AUTOSAR XML (schema 00050)
package /ComponentTypes
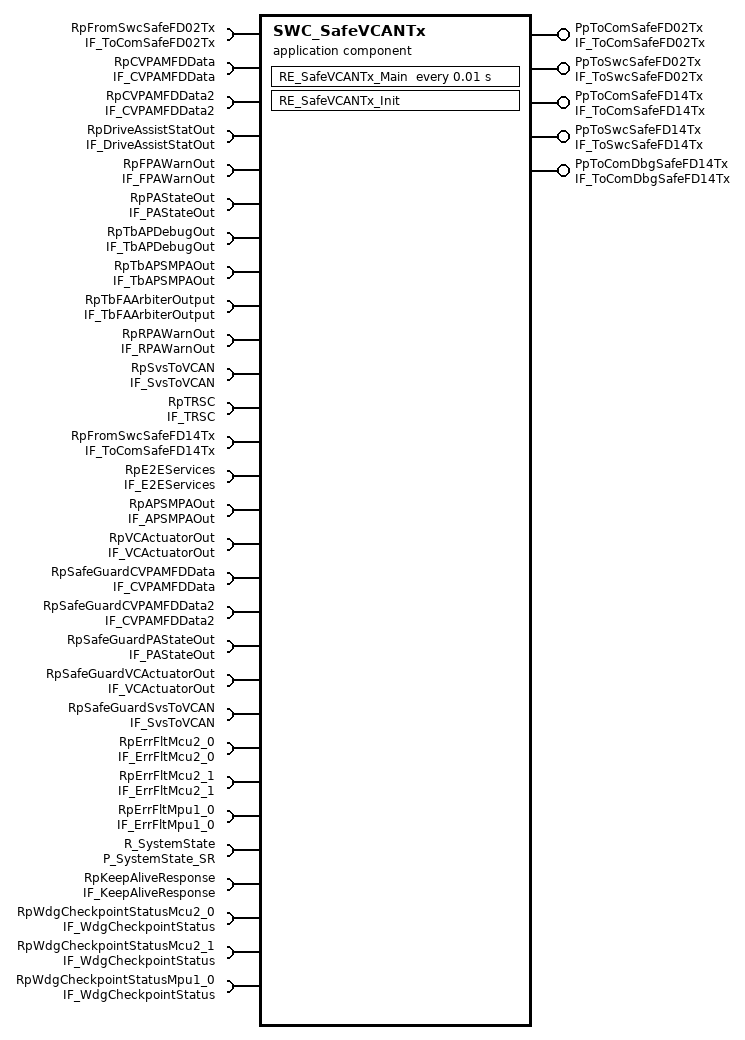
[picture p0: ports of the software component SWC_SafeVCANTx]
  application sw component type SWC_SafeVCANTx
    provide port PpToComSafeFD02Tx: provided-interface=IF_ToComSafeFD02Tx
      provided-com-specs:
        data-element=Reserved_for_functional_safety, init-value=0
        data-element=Segment_1_Confidence, init-value=0
        data-element=Segment_1_ID, init-value=0
        data-element=Segment_1_X1, init-value=0
        data-element=Segment_1_X2, init-value=0
        data-element=Segment_1_Y1, init-value=0
        data-element=Segment_1_Y2, init-value=0
        data-element=Segment_2_Confidence, init-value=0
        data-element=Segment_2_ID, init-value=0
        data-element=Segment_2_X1, init-value=0
        data-element=Segment_2_X2, init-value=0
        data-element=Segment_2_Y1, init-value=0
        data-element=Segment_2_Y2, init-value=0
        data-element=Segment_3_Confidence, init-value=0
        data-element=Segment_3_ID, init-value=0
        data-element=Segment_3_X1, init-value=0
        data-element=Segment_3_X2, init-value=0
        data-element=Segment_3_Y1, init-value=0
        data-element=Segment_3_Y2, init-value=0
        data-element=Segment_4_Confidence, init-value=0
        data-element=Segment_4_ID, init-value=0
        data-element=Segment_4_X1, init-value=0
        data-element=Segment_4_X2, init-value=0
        data-element=Segment_4_Y1, init-value=0
        data-element=Segment_4_Y2, init-value=0
        data-element=Segment_5_Confidence, init-value=0
        data-element=Segment_5_ID, init-value=0
        data-element=Segment_5_X1, init-value=0
        data-element=Segment_5_X2, init-value=0
        data-element=Segment_5_Y1, init-value=0
        data-element=Segment_5_Y2, init-value=0
        data-element=Segment_6_Confidence, init-value=0
        data-element=Segment_6_ID, init-value=0
        data-element=Segment_6_X1, init-value=0
        data-element=Segment_6_X2, init-value=0
        data-element=Segment_6_Y1, init-value=0
        data-element=Segment_6_Y2, init-value=0
        data-element=Segment_7_Confidence, init-value=0
        data-element=Segment_7_ID, init-value=0
        data-element=Segment_7_X1, init-value=0
        data-element=Segment_7_X2, init-value=0
        data-element=Segment_7_Y1, init-value=0
        data-element=Segment_7_Y2, init-value=0
        data-element=Segment_8_Confidence, init-value=0
        data-element=Segment_8_ID, init-value=0
        data-element=Segment_8_X1, init-value=0
        data-element=Segment_8_X2, init-value=0
        data-element=Segment_8_Y1, init-value=0
        data-element=Segment_8_Y2, init-value=0
        data-element=Camera_Status, init-value=0
        data-element=Cntr_ADAS_FD_LANES_1, init-value=0
        data-element=Cntr_ADAS_FD_LANES_2, init-value=0
        data-element=FOD_Confidence, init-value=0
        data-element=Frame_Index_Lanes_1, init-value=0
        data-element=Frame_Index_Lanes_2, init-value=0
        data-element=Health_Front_Object_Detection, init-value=0
        data-element=Health_Lane_Detection, init-value=0
        data-element=Line_1_Confidence, init-value=0
        data-element=Line_1_Curvature, init-value=0
        data-element=Line_1_Curvature_Rate, init-value=0
        data-element=Line_1_End_Range, init-value=0
        data-element=Line_1_Heading, init-value=0
        data-element=Line_1_Offset, init-value=0
        data-element=Line_1_Start_Range, init-value=0
        data-element=Line_1_Type, init-value=0
        data-element=Line_2_Confidence, init-value=0
        data-element=Line_2_Curvature, init-value=0
        data-element=Line_2_Curvature_Rate, init-value=0
        data-element=Line_2_End_Range, init-value=0
        data-element=Line_2_Heading, init-value=0
        data-element=Line_2_Offset, init-value=0
        data-element=Line_2_Start_Range, init-value=0
        data-element=Line_2_Type, init-value=0
        data-element=Line_3_Confidence, init-value=0
        data-element=Line_3_Curvature, init-value=0
        data-element=Line_3_Curvature_Rate, init-value=0
        data-element=Line_3_End_Range, init-value=0
        data-element=Line_3_Heading, init-value=0
        data-element=Line_3_Offset, init-value=0
        data-element=Line_3_Start_Range, init-value=0
        data-element=Line_3_Type, init-value=0
        data-element=Line_4_Confidence, init-value=0
        data-element=Line_4_Curvature, init-value=0
        data-element=Line_4_Curvature_Rate, init-value=0
        data-element=Line_4_End_Range, init-value=0
        data-element=Line_4_Heading, init-value=0
        data-element=Line_4_Offset, init-value=0
        data-element=Line_4_Start_Range, init-value=0
        data-element=Line_4_Type, init-value=0
        {data-element=MAC_ADAS_FD_LANES_1, init-value=[rule-based-values={rule=FILL_UNTIL_END, rule-arguments=0}]}
        {data-element=MAC_ADAS_FD_LANES_2, init-value=[rule-based-values={rule=FILL_UNTIL_END, rule-arguments=0}]}
        data-element=Alert_CHF, init-value=0
        data-element=Alert_CHR, init-value=0
        data-element=Alert_LHF, init-value=0
        data-element=Alert_LHR, init-value=0
        data-element=Alert_RHF, init-value=0
        data-element=Alert_RHR, init-value=0
        data-element=AUXCamsRQSts, init-value=0
        data-element=ChimeActivation_LHF, init-value=0
        data-element=ChimeActivation_LHR, init-value=0
        data-element=ChimeActivation_RHF, init-value=0
        data-element=ChimeActivation_RHR, init-value=0
        data-element=DisplayView2, init-value=0
        data-element=FrontSensorSts, init-value=0
        data-element=FT_PAM_LedControlSts, init-value=0
        data-element=Graphic_CHF, init-value=0
        data-element=Graphic_CHR, init-value=0
        data-element=Graphic_LHF, init-value=0
        data-element=Graphic_LHR, init-value=0
        data-element=Graphic_RHF, init-value=0
        data-element=Graphic_RHR, init-value=0
        data-element=HMICode, init-value=0
        data-element=ImageDefeatRQSts, init-value=0
        data-element=MoreCamsRQSts, init-value=0
        data-element=PAM_CHIME_REP_RATESts, init-value=0
        data-element=PAM_CHIME_TYPE, init-value=0
        data-element=PAM_LedControlSts, init-value=0
        data-element=PAM_Off_Status, init-value=0
        data-element=PAM_Off_Status_2BT, init-value=0
        data-element=PAM_PopUpRqst, init-value=0
        data-element=PAM_Volume, init-value=0
        data-element=PAMSystemFault, init-value=0
        data-element=ParkingManeuverActive, init-value=0
        data-element=PPPA_TurnIndicatorRqst, init-value=0
        data-element=RearSensorSts, init-value=0
        data-element=RR_PAM_Brk_RqSts, init-value=0
        data-element=RR_PAM_Dist, init-value=0
        data-element=RR_PAM_StopControlSts, init-value=0
        data-element=SPM_LedControlSts, init-value=0
        data-element=SPM_Screen_Rqst, init-value=0
        data-element=SPMControlSts, init-value=0
        data-element=SPMFailSts, init-value=0
        data-element=SPMSystemFault, init-value=0
        data-element=TRSC_LED_Stat, init-value=0
    require port RpFromSwcSafeFD02Tx: required-interface=IF_ToComSafeFD02Tx
      required-com-specs:
        data-element=Reserved_for_functional_safety, filter=data-filter-type=ALWAYS, init-value=0
        data-element=Segment_1_Confidence, filter=data-filter-type=ALWAYS, init-value=0
        data-element=Segment_1_ID, filter=data-filter-type=ALWAYS, init-value=0
        data-element=Segment_1_X1, filter=data-filter-type=ALWAYS, init-value=0
        data-element=Segment_1_X2, filter=data-filter-type=ALWAYS, init-value=0
        data-element=Segment_1_Y1, filter=data-filter-type=ALWAYS, init-value=0
        data-element=Segment_1_Y2, filter=data-filter-type=ALWAYS, init-value=0
        data-element=Segment_2_Confidence, filter=data-filter-type=ALWAYS, init-value=0
        data-element=Segment_2_ID, filter=data-filter-type=ALWAYS, init-value=0
        data-element=Segment_2_X1, filter=data-filter-type=ALWAYS, init-value=0
        data-element=Segment_2_X2, filter=data-filter-type=ALWAYS, init-value=0
        data-element=Segment_2_Y1, filter=data-filter-type=ALWAYS, init-value=0
        data-element=Segment_2_Y2, filter=data-filter-type=ALWAYS, init-value=0
        data-element=Segment_3_Confidence, filter=data-filter-type=ALWAYS, init-value=0
        data-element=Segment_3_ID, filter=data-filter-type=ALWAYS, init-value=0
        data-element=Segment_3_X1, filter=data-filter-type=ALWAYS, init-value=0
        data-element=Segment_3_X2, filter=data-filter-type=ALWAYS, init-value=0
        data-element=Segment_3_Y1, filter=data-filter-type=ALWAYS, init-value=0
        data-element=Segment_3_Y2, filter=data-filter-type=ALWAYS, init-value=0
        data-element=Segment_4_Confidence, filter=data-filter-type=ALWAYS, init-value=0
        data-element=Segment_4_ID, filter=data-filter-type=ALWAYS, init-value=0
        data-element=Segment_4_X1, filter=data-filter-type=ALWAYS, init-value=0
        data-element=Segment_4_X2, filter=data-filter-type=ALWAYS, init-value=0
        data-element=Segment_4_Y1, filter=data-filter-type=ALWAYS, init-value=0
        data-element=Segment_4_Y2, filter=data-filter-type=ALWAYS, init-value=0
        data-element=Segment_5_Confidence, filter=data-filter-type=ALWAYS, init-value=0
        data-element=Segment_5_ID, filter=data-filter-type=ALWAYS, init-value=0
        data-element=Segment_5_X1, filter=data-filter-type=ALWAYS, init-value=0
        data-element=Segment_5_X2, filter=data-filter-type=ALWAYS, init-value=0
        data-element=Segment_5_Y1, filter=data-filter-type=ALWAYS, init-value=0
        data-element=Segment_5_Y2, filter=data-filter-type=ALWAYS, init-value=0
        data-element=Segment_6_Confidence, filter=data-filter-type=ALWAYS, init-value=0
        data-element=Segment_6_ID, filter=data-filter-type=ALWAYS, init-value=0
        data-element=Segment_6_X1, filter=data-filter-type=ALWAYS, init-value=0
        data-element=Segment_6_X2, filter=data-filter-type=ALWAYS, init-value=0
        data-element=Segment_6_Y1, filter=data-filter-type=ALWAYS, init-value=0
        data-element=Segment_6_Y2, filter=data-filter-type=ALWAYS, init-value=0
        data-element=Segment_7_Confidence, filter=data-filter-type=ALWAYS, init-value=0
        data-element=Segment_7_ID, filter=data-filter-type=ALWAYS, init-value=0
        data-element=Segment_7_X1, filter=data-filter-type=ALWAYS, init-value=0
        data-element=Segment_7_X2, filter=data-filter-type=ALWAYS, init-value=0
        data-element=Segment_7_Y1, filter=data-filter-type=ALWAYS, init-value=0
        data-element=Segment_7_Y2, filter=data-filter-type=ALWAYS, init-value=0
        data-element=Segment_8_Confidence, filter=data-filter-type=ALWAYS, init-value=0
        data-element=Segment_8_ID, filter=data-filter-type=ALWAYS, init-value=0
        data-element=Segment_8_X1, filter=data-filter-type=ALWAYS, init-value=0
        data-element=Segment_8_X2, filter=data-filter-type=ALWAYS, init-value=0
        data-element=Segment_8_Y1, filter=data-filter-type=ALWAYS, init-value=0
        data-element=Segment_8_Y2, filter=data-filter-type=ALWAYS, init-value=0
        data-element=Camera_Status, filter=data-filter-type=ALWAYS, init-value=0
        data-element=Cntr_ADAS_FD_LANES_1, filter=data-filter-type=ALWAYS, init-value=0
        data-element=Cntr_ADAS_FD_LANES_2, filter=data-filter-type=ALWAYS, init-value=0
        data-element=FOD_Confidence, filter=data-filter-type=ALWAYS, init-value=0
        data-element=Frame_Index_Lanes_1, filter=data-filter-type=ALWAYS, init-value=0
        data-element=Frame_Index_Lanes_2, filter=data-filter-type=ALWAYS, init-value=0
        data-element=Health_Front_Object_Detection, filter=data-filter-type=ALWAYS, init-value=0
        data-element=Health_Lane_Detection, filter=data-filter-type=ALWAYS, init-value=0
        data-element=Line_1_Confidence, filter=data-filter-type=ALWAYS, init-value=0
        data-element=Line_1_Curvature, filter=data-filter-type=ALWAYS, init-value=0
        data-element=Line_1_Curvature_Rate, filter=data-filter-type=ALWAYS, init-value=0
        data-element=Line_1_End_Range, filter=data-filter-type=ALWAYS, init-value=0
        data-element=Line_1_Heading, filter=data-filter-type=ALWAYS, init-value=0
        data-element=Line_1_Offset, filter=data-filter-type=ALWAYS, init-value=0
        data-element=Line_1_Start_Range, filter=data-filter-type=ALWAYS, init-value=0
        data-element=Line_1_Type, filter=data-filter-type=ALWAYS, init-value=0
        data-element=Line_2_Confidence, filter=data-filter-type=ALWAYS, init-value=0
        data-element=Line_2_Curvature, filter=data-filter-type=ALWAYS, init-value=0
        data-element=Line_2_Curvature_Rate, filter=data-filter-type=ALWAYS, init-value=0
        data-element=Line_2_End_Range, filter=data-filter-type=ALWAYS, init-value=0
        data-element=Line_2_Heading, filter=data-filter-type=ALWAYS, init-value=0
        data-element=Line_2_Offset, filter=data-filter-type=ALWAYS, init-value=0
        data-element=Line_2_Start_Range, filter=data-filter-type=ALWAYS, init-value=0
        data-element=Line_2_Type, filter=data-filter-type=ALWAYS, init-value=0
        data-element=Line_3_Confidence, filter=data-filter-type=ALWAYS, init-value=0
        data-element=Line_3_Curvature, filter=data-filter-type=ALWAYS, init-value=0
        data-element=Line_3_Curvature_Rate, filter=data-filter-type=ALWAYS, init-value=0
        data-element=Line_3_End_Range, filter=data-filter-type=ALWAYS, init-value=0
        data-element=Line_3_Heading, filter=data-filter-type=ALWAYS, init-value=0
        data-element=Line_3_Offset, filter=data-filter-type=ALWAYS, init-value=0
        data-element=Line_3_Start_Range, filter=data-filter-type=ALWAYS, init-value=0
        data-element=Line_3_Type, filter=data-filter-type=ALWAYS, init-value=0
        data-element=Line_4_Confidence, filter=data-filter-type=ALWAYS, init-value=0
        data-element=Line_4_Curvature, filter=data-filter-type=ALWAYS, init-value=0
        data-element=Line_4_Curvature_Rate, filter=data-filter-type=ALWAYS, init-value=0
        data-element=Line_4_End_Range, filter=data-filter-type=ALWAYS, init-value=0
        data-element=Line_4_Heading, filter=data-filter-type=ALWAYS, init-value=0
        data-element=Line_4_Offset, filter=data-filter-type=ALWAYS, init-value=0
        data-element=Line_4_Start_Range, filter=data-filter-type=ALWAYS, init-value=0
        data-element=Line_4_Type, filter=data-filter-type=ALWAYS, init-value=0
        {data-element=MAC_ADAS_FD_LANES_1, filter=data-filter-type=ALWAYS, init-value=[rule-based-values={rule=FILL_UNTIL_END, rule-arguments=0}]}
        {data-element=MAC_ADAS_FD_LANES_2, filter=data-filter-type=ALWAYS, init-value=[rule-based-values={rule=FILL_UNTIL_END, rule-arguments=0}]}
        data-element=Alert_CHF, filter=data-filter-type=ALWAYS, init-value=0
        data-element=Alert_CHR, filter=data-filter-type=ALWAYS, init-value=0
        data-element=Alert_LHF, filter=data-filter-type=ALWAYS, init-value=0
        data-element=Alert_LHR, filter=data-filter-type=ALWAYS, init-value=0
        data-element=Alert_RHF, filter=data-filter-type=ALWAYS, init-value=0
        data-element=Alert_RHR, filter=data-filter-type=ALWAYS, init-value=0
        data-element=AUXCamsRQSts, filter=data-filter-type=ALWAYS, init-value=0
        data-element=ChimeActivation_LHF, filter=data-filter-type=ALWAYS, init-value=0
        data-element=ChimeActivation_LHR, filter=data-filter-type=ALWAYS, init-value=0
        data-element=ChimeActivation_RHF, filter=data-filter-type=ALWAYS, init-value=0
        data-element=ChimeActivation_RHR, filter=data-filter-type=ALWAYS, init-value=0
        data-element=DisplayView2, filter=data-filter-type=ALWAYS, init-value=0
        data-element=FrontSensorSts, filter=data-filter-type=ALWAYS, init-value=0
        data-element=FT_PAM_LedControlSts, filter=data-filter-type=ALWAYS, init-value=0
        data-element=Graphic_CHF, filter=data-filter-type=ALWAYS, init-value=0
        data-element=Graphic_CHR, filter=data-filter-type=ALWAYS, init-value=0
        data-element=Graphic_LHF, filter=data-filter-type=ALWAYS, init-value=0
        data-element=Graphic_LHR, filter=data-filter-type=ALWAYS, init-value=0
        data-element=Graphic_RHF, filter=data-filter-type=ALWAYS, init-value=0
        data-element=Graphic_RHR, filter=data-filter-type=ALWAYS, init-value=0
        data-element=HMICode, filter=data-filter-type=ALWAYS, init-value=0
        data-element=ImageDefeatRQSts, filter=data-filter-type=ALWAYS, init-value=0
        data-element=MoreCamsRQSts, filter=data-filter-type=ALWAYS, init-value=0
        data-element=PAM_CHIME_REP_RATESts, filter=data-filter-type=ALWAYS, init-value=0
        data-element=PAM_CHIME_TYPE, filter=data-filter-type=ALWAYS, init-value=0
        data-element=PAM_LedControlSts, filter=data-filter-type=ALWAYS, init-value=0
        data-element=PAM_Off_Status, filter=data-filter-type=ALWAYS, init-value=0
        data-element=PAM_Off_Status_2BT, filter=data-filter-type=ALWAYS, init-value=0
        data-element=PAM_PopUpRqst, filter=data-filter-type=ALWAYS, init-value=0
        data-element=PAM_Volume, filter=data-filter-type=ALWAYS, init-value=0
        data-element=PAMSystemFault, filter=data-filter-type=ALWAYS, init-value=0
        data-element=ParkingManeuverActive, filter=data-filter-type=ALWAYS, init-value=0
        data-element=PPPA_TurnIndicatorRqst, filter=data-filter-type=ALWAYS, init-value=0
        data-element=RearSensorSts, filter=data-filter-type=ALWAYS, init-value=0
        data-element=RR_PAM_Brk_RqSts, filter=data-filter-type=ALWAYS, init-value=0
        data-element=RR_PAM_Dist, filter=data-filter-type=ALWAYS, init-value=0
        data-element=RR_PAM_StopControlSts, filter=data-filter-type=ALWAYS, init-value=0
        data-element=SPM_LedControlSts, filter=data-filter-type=ALWAYS, init-value=0
        data-element=SPM_Screen_Rqst, filter=data-filter-type=ALWAYS, init-value=0
        data-element=SPMControlSts, filter=data-filter-type=ALWAYS, init-value=0
        data-element=SPMFailSts, filter=data-filter-type=ALWAYS, init-value=0
        data-element=SPMSystemFault, filter=data-filter-type=ALWAYS, init-value=0
        data-element=TRSC_LED_Stat, filter=data-filter-type=ALWAYS, init-value=0
    provide port PpToSwcSafeFD02Tx: provided-interface=IF_ToSwcSafeFD02Tx
      provided-com-specs:
        data-element=Reserved_for_functional_safety, init-value=0
        data-element=Segment_1_Confidence, init-value=0
        data-element=Segment_1_ID, init-value=0
        data-element=Segment_1_X1, init-value=0
        data-element=Segment_1_X2, init-value=0
        data-element=Segment_1_Y1, init-value=0
        data-element=Segment_1_Y2, init-value=0
        data-element=Segment_2_Confidence, init-value=0
        data-element=Segment_2_ID, init-value=0
        data-element=Segment_2_X1, init-value=0
        data-element=Segment_2_X2, init-value=0
        data-element=Segment_2_Y1, init-value=0
        data-element=Segment_2_Y2, init-value=0
        data-element=Segment_3_Confidence, init-value=0
        data-element=Segment_3_ID, init-value=0
        data-element=Segment_3_X1, init-value=0
        data-element=Segment_3_X2, init-value=0
        data-element=Segment_3_Y1, init-value=0
        data-element=Segment_3_Y2, init-value=0
        data-element=Segment_4_Confidence, init-value=0
        data-element=Segment_4_ID, init-value=0
        data-element=Segment_4_X1, init-value=0
        data-element=Segment_4_X2, init-value=0
        data-element=Segment_4_Y1, init-value=0
        data-element=Segment_4_Y2, init-value=0
        data-element=Segment_5_Confidence, init-value=0
        data-element=Segment_5_ID, init-value=0
        data-element=Segment_5_X1, init-value=0
        data-element=Segment_5_X2, init-value=0
        data-element=Segment_5_Y1, init-value=0
        data-element=Segment_5_Y2, init-value=0
        data-element=Segment_6_Confidence, init-value=0
        data-element=Segment_6_ID, init-value=0
        data-element=Segment_6_X1, init-value=0
        data-element=Segment_6_X2, init-value=0
        data-element=Segment_6_Y1, init-value=0
        data-element=Segment_6_Y2, init-value=0
        data-element=Segment_7_Confidence, init-value=0
        data-element=Segment_7_ID, init-value=0
        data-element=Segment_7_X1, init-value=0
        data-element=Segment_7_X2, init-value=0
        data-element=Segment_7_Y1, init-value=0
        data-element=Segment_7_Y2, init-value=0
        data-element=Segment_8_Confidence, init-value=0
        data-element=Segment_8_ID, init-value=0
        data-element=Segment_8_X1, init-value=0
        data-element=Segment_8_X2, init-value=0
        data-element=Segment_8_Y1, init-value=0
        data-element=Segment_8_Y2, init-value=0
        data-element=Camera_Status, init-value=0
        data-element=Cntr_ADAS_FD_LANES_1, init-value=0
        data-element=Cntr_ADAS_FD_LANES_2, init-value=0
        data-element=FOD_Confidence, init-value=0
        data-element=Frame_Index_Lanes_1, init-value=0
        data-element=Frame_Index_Lanes_2, init-value=0
        data-element=Health_Front_Object_Detection, init-value=0
        data-element=Health_Lane_Detection, init-value=0
        data-element=Line_1_Confidence, init-value=0
        data-element=Line_1_Curvature, init-value=0
        data-element=Line_1_Curvature_Rate, init-value=0
        data-element=Line_1_End_Range, init-value=0
        data-element=Line_1_Heading, init-value=0
        data-element=Line_1_Offset, init-value=0
        data-element=Line_1_Start_Range, init-value=0
        data-element=Line_1_Type, init-value=0
        data-element=Line_2_Confidence, init-value=0
        data-element=Line_2_Curvature, init-value=0
        data-element=Line_2_Curvature_Rate, init-value=0
        data-element=Line_2_End_Range, init-value=0
        data-element=Line_2_Heading, init-value=0
        data-element=Line_2_Offset, init-value=0
        data-element=Line_2_Start_Range, init-value=0
        data-element=Line_2_Type, init-value=0
        data-element=Line_3_Confidence, init-value=0
        data-element=Line_3_Curvature, init-value=0
        data-element=Line_3_Curvature_Rate, init-value=0
        data-element=Line_3_End_Range, init-value=0
        data-element=Line_3_Heading, init-value=0
        data-element=Line_3_Offset, init-value=0
        data-element=Line_3_Start_Range, init-value=0
        data-element=Line_3_Type, init-value=0
        data-element=Line_4_Confidence, init-value=0
        data-element=Line_4_Curvature, init-value=0
        data-element=Line_4_Curvature_Rate, init-value=0
        data-element=Line_4_End_Range, init-value=0
        data-element=Line_4_Heading, init-value=0
        data-element=Line_4_Offset, init-value=0
        data-element=Line_4_Start_Range, init-value=0
        data-element=Line_4_Type, init-value=0
        {data-element=MAC_ADAS_FD_LANES_1, init-value=[rule-based-values={rule=FILL_UNTIL_END, rule-arguments=0}]}
        {data-element=MAC_ADAS_FD_LANES_2, init-value=[rule-based-values={rule=FILL_UNTIL_END, rule-arguments=0}]}
        data-element=Alert_CHF, init-value=0
        data-element=Alert_CHR, init-value=0
        data-element=Alert_LHF, init-value=0
        data-element=Alert_LHR, init-value=0
        data-element=Alert_RHF, init-value=0
        data-element=Alert_RHR, init-value=0
        data-element=AUXCamsRQSts, init-value=0
        data-element=ChimeActivation_LHF, init-value=0
        data-element=ChimeActivation_LHR, init-value=0
        data-element=ChimeActivation_RHF, init-value=0
        data-element=ChimeActivation_RHR, init-value=0
        data-element=DisplayView2, init-value=0
        data-element=FrontSensorSts, init-value=0
        data-element=FT_PAM_LedControlSts, init-value=0
        data-element=Graphic_CHF, init-value=0
        data-element=Graphic_CHR, init-value=0
        data-element=Graphic_LHF, init-value=0
        data-element=Graphic_LHR, init-value=0
        data-element=Graphic_RHF, init-value=0
        data-element=Graphic_RHR, init-value=0
        data-element=HMICode, init-value=0
        data-element=ImageDefeatRQSts, init-value=0
        data-element=MoreCamsRQSts, init-value=0
        data-element=PAM_CHIME_REP_RATESts, init-value=0
        data-element=PAM_CHIME_TYPE, init-value=0
        data-element=PAM_LedControlSts, init-value=0
        data-element=PAM_Off_Status, init-value=0
        data-element=PAM_Off_Status_2BT, init-value=0
        data-element=PAM_PopUpRqst, init-value=0
        data-element=PAM_Volume, init-value=0
        data-element=PAMSystemFault, init-value=0
        data-element=ParkingManeuverActive, init-value=0
        data-element=PPPA_TurnIndicatorRqst, init-value=0
        data-element=RearSensorSts, init-value=0
        data-element=RR_PAM_Brk_RqSts, init-value=0
        data-element=RR_PAM_Dist, init-value=0
        data-element=RR_PAM_StopControlSts, init-value=0
        data-element=SPM_LedControlSts, init-value=0
        data-element=SPM_Screen_Rqst, init-value=0
        data-element=SPMControlSts, init-value=0
        data-element=SPMFailSts, init-value=0
        data-element=SPMSystemFault, init-value=0
        data-element=TRSC_LED_Stat, init-value=0
    11 x require port:
      RpCVPAMFDData: nonqueued-receiver-com-spec=data-element=IFOD_Outputs_CVPAMFDData_t, required-interface=IF_CVPAMFDData
      RpCVPAMFDData2: nonqueued-receiver-com-spec=data-element=LMD_Outputs_CVPAMFDData2_t, required-interface=IF_CVPAMFDData2
      RpDriveAssistStatOut: nonqueued-receiver-com-spec=data-element=TbAP_DriveAssistStatOut_t, required-interface=IF_DriveAssistStatOut
      RpFPAWarnOut: nonqueued-receiver-com-spec=data-element=TbAP_FPAWarnOut_t, required-interface=IF_FPAWarnOut
      RpPAStateOut: nonqueued-receiver-com-spec=data-element=TbAP_PAStateOut_t, required-interface=IF_PAStateOut
      RpTbAPDebugOut: nonqueued-receiver-com-spec=data-element=TbAP_DebugOut, required-interface=IF_TbAPDebugOut
      RpTbAPSMPAOut: nonqueued-receiver-com-spec=data-element=TbAP_SMPAInternalOut_t, required-interface=IF_TbAPSMPAOut
      RpTbFAArbiterOutput: nonqueued-receiver-com-spec{data-element=TbFA_ArbiterOutput_t, filter=data-filter-type=ALWAYS}, required-interface=IF_TbFAArbiterOutput
      RpRPAWarnOut: nonqueued-receiver-com-spec=data-element=TbAP_RPAWarnOut_t, required-interface=IF_RPAWarnOut
      RpSvsToVCAN: nonqueued-receiver-com-spec=data-element=SvsToVCAN_t, required-interface=IF_SvsToVCAN
      RpTRSC: nonqueued-receiver-com-spec=data-element=ME_VehOut_TRSC_t, required-interface=IF_TRSC
    provide port PpToComSafeFD14Tx: provided-interface=IF_ToComSafeFD14Tx
      provided-com-specs:
        data-element=FD14_Camera_Status, init-value=0
        data-element=FD14_Cntr_ADAS_FD_LANES_1, init-value=0
        data-element=FD14_Cntr_ADAS_FD_LANES_2, init-value=0
        data-element=FD14_FOD_Confidence, init-value=0
        data-element=FD14_Frame_Index_Lanes_1, init-value=0
        data-element=FD14_Frame_Index_Lanes_2, init-value=0
        data-element=FD14_Health_Front_Object_Detection, init-value=0
        data-element=FD14_Health_Lane_Detection, init-value=0
        data-element=FD14_Line_1_Confidence, init-value=0
        data-element=FD14_Line_1_Curvature, init-value=0
        data-element=FD14_Line_1_Curvature_Rate, init-value=0
        data-element=FD14_Line_1_End_Range, init-value=0
        data-element=FD14_Line_1_Heading, init-value=0
        data-element=FD14_Line_1_Offset, init-value=0
        data-element=FD14_Line_1_Start_Range, init-value=0
        data-element=FD14_Line_1_Type, init-value=0
        data-element=FD14_Line_2_Confidence, init-value=0
        data-element=FD14_Line_2_Curvature, init-value=0
        data-element=FD14_Line_2_Curvature_Rate, init-value=0
        data-element=FD14_Line_2_End_Range, init-value=0
        data-element=FD14_Line_2_Heading, init-value=0
        data-element=FD14_Line_2_Offset, init-value=0
        data-element=FD14_Line_2_Start_Range, init-value=0
        data-element=FD14_Line_2_Type, init-value=0
        data-element=FD14_Line_3_Confidence, init-value=0
        data-element=FD14_Line_3_Curvature, init-value=0
        data-element=FD14_Line_3_Curvature_Rate, init-value=0
        data-element=FD14_Line_3_End_Range, init-value=0
        data-element=FD14_Line_3_Heading, init-value=0
        data-element=FD14_Line_3_Offset, init-value=0
        data-element=FD14_Line_3_Start_Range, init-value=0
        data-element=FD14_Line_3_Type, init-value=0
        data-element=FD14_Line_4_Confidence, init-value=0
        data-element=FD14_Line_4_Curvature, init-value=0
        data-element=FD14_Line_4_Curvature_Rate, init-value=0
        data-element=FD14_Line_4_End_Range, init-value=0
        data-element=FD14_Line_4_Heading, init-value=0
        data-element=FD14_Line_4_Offset, init-value=0
        data-element=FD14_Line_4_Start_Range, init-value=0
        data-element=FD14_Line_4_Type, init-value=0
        {data-element=FD14_MAC_ADAS_FD_LANES_1, init-value=[rule-based-values={rule=FILL_UNTIL_END, rule-arguments=0}]}
        {data-element=FD14_MAC_ADAS_FD_LANES_2, init-value=[rule-based-values={rule=FILL_UNTIL_END, rule-arguments=0}]}
        data-element=FD14_ParkingManeuverActive, init-value=0
        data-element=FD14_Reserved_for_functional_safety, init-value=0
        data-element=FD14_Segment_1_Confidence, init-value=0
        data-element=FD14_Segment_1_ID, init-value=0
        data-element=FD14_Segment_1_X1, init-value=0
        data-element=FD14_Segment_1_X2, init-value=0
        data-element=FD14_Segment_1_Y1, init-value=0
        data-element=FD14_Segment_1_Y2, init-value=0
        data-element=FD14_Segment_2_Confidence, init-value=0
        data-element=FD14_Segment_2_ID, init-value=0
        data-element=FD14_Segment_2_X1, init-value=0
        data-element=FD14_Segment_2_X2, init-value=0
        data-element=FD14_Segment_2_Y1, init-value=0
        data-element=FD14_Segment_2_Y2, init-value=0
        data-element=FD14_Segment_3_Confidence, init-value=0
        data-element=FD14_Segment_3_ID, init-value=0
        data-element=FD14_Segment_3_X1, init-value=0
        data-element=FD14_Segment_3_X2, init-value=0
        data-element=FD14_Segment_3_Y1, init-value=0
        data-element=FD14_Segment_3_Y2, init-value=0
        data-element=FD14_Segment_4_Confidence, init-value=0
        data-element=FD14_Segment_4_ID, init-value=0
        data-element=FD14_Segment_4_X1, init-value=0
        data-element=FD14_Segment_4_X2, init-value=0
        data-element=FD14_Segment_4_Y1, init-value=0
        data-element=FD14_Segment_4_Y2, init-value=0
        data-element=FD14_Segment_5_Confidence, init-value=0
        data-element=FD14_Segment_5_ID, init-value=0
        data-element=FD14_Segment_5_X1, init-value=0
        data-element=FD14_Segment_5_X2, init-value=0
        data-element=FD14_Segment_5_Y1, init-value=0
        data-element=FD14_Segment_5_Y2, init-value=0
        data-element=FD14_Segment_6_Confidence, init-value=0
        data-element=FD14_Segment_6_ID, init-value=0
        data-element=FD14_Segment_6_X1, init-value=0
        data-element=FD14_Segment_6_X2, init-value=0
        data-element=FD14_Segment_6_Y1, init-value=0
        data-element=FD14_Segment_6_Y2, init-value=0
        data-element=FD14_Segment_7_Confidence, init-value=0
        data-element=FD14_Segment_7_ID, init-value=0
        data-element=FD14_Segment_7_X1, init-value=0
        data-element=FD14_Segment_7_X2, init-value=0
        data-element=FD14_Segment_7_Y1, init-value=0
        data-element=FD14_Segment_7_Y2, init-value=0
        data-element=FD14_Segment_8_Confidence, init-value=0
        data-element=FD14_Segment_8_ID, init-value=0
        data-element=FD14_Segment_8_X1, init-value=0
        data-element=FD14_Segment_8_X2, init-value=0
        data-element=FD14_Segment_8_Y1, init-value=0
        data-element=FD14_Segment_8_Y2, init-value=0
        data-element=FD14_ManoeuvrePhase, init-value=0
        data-element=FD14_ParkingGearShiftReq, init-value=0
        data-element=FD14_PPPA_AccelMax, init-value=0
        data-element=FD14_PPPA_AccelMin, init-value=0
        data-element=FD14_PPPA_DecelMax, init-value=0
        data-element=FD14_PPPA_DecelMin, init-value=0
        data-element=FD14_PPPA_Interface_BSM, init-value=0
        data-element=FD14_PPPA_JerkAccelMax, init-value=0
        data-element=FD14_PPPA_JerkAccelMin, init-value=0
        data-element=FD14_PPPA_JerkDecelMax, init-value=0
        data-element=FD14_PPPA_JerkDecelMin, init-value=0
        data-element=FD14_PPPA_MaxSpeed, init-value=0
        data-element=FD14_PPPA_StandstillRqst, init-value=0
        data-element=FD14_PPPA_TargetDistance, init-value=0
        data-element=FD14_RR_PAM_Brk_RqSts, init-value=0
        data-element=FD14_RR_PAM_Dist, init-value=0
        data-element=FD14_SPM_Lat_Ctrl_RequestSts, init-value=0
        data-element=FD14_TorqueOverlaySteeringReq_SPM, init-value=1024
    provide port PpToSwcSafeFD14Tx: provided-interface=IF_ToSwcSafeFD14Tx
      provided-com-specs:
        data-element=FD14_Camera_Status, init-value=0
        data-element=FD14_Cntr_ADAS_FD_LANES_1, init-value=0
        data-element=FD14_Cntr_ADAS_FD_LANES_2, init-value=0
        data-element=FD14_FOD_Confidence, init-value=0
        data-element=FD14_Frame_Index_Lanes_1, init-value=0
        data-element=FD14_Frame_Index_Lanes_2, init-value=0
        data-element=FD14_Health_Front_Object_Detection, init-value=0
        data-element=FD14_Health_Lane_Detection, init-value=0
        data-element=FD14_Line_1_Confidence, init-value=0
        data-element=FD14_Line_1_Curvature, init-value=0
        data-element=FD14_Line_1_Curvature_Rate, init-value=0
        data-element=FD14_Line_1_End_Range, init-value=0
        data-element=FD14_Line_1_Heading, init-value=0
        data-element=FD14_Line_1_Offset, init-value=0
        data-element=FD14_Line_1_Start_Range, init-value=0
        data-element=FD14_Line_1_Type, init-value=0
        data-element=FD14_Line_2_Confidence, init-value=0
        data-element=FD14_Line_2_Curvature, init-value=0
        data-element=FD14_Line_2_Curvature_Rate, init-value=0
        data-element=FD14_Line_2_End_Range, init-value=0
        data-element=FD14_Line_2_Heading, init-value=0
        data-element=FD14_Line_2_Offset, init-value=0
        data-element=FD14_Line_2_Start_Range, init-value=0
        data-element=FD14_Line_2_Type, init-value=0
        data-element=FD14_Line_3_Confidence, init-value=0
        data-element=FD14_Line_3_Curvature, init-value=0
        data-element=FD14_Line_3_Curvature_Rate, init-value=0
        data-element=FD14_Line_3_End_Range, init-value=0
        data-element=FD14_Line_3_Heading, init-value=0
        data-element=FD14_Line_3_Offset, init-value=0
        data-element=FD14_Line_3_Start_Range, init-value=0
        data-element=FD14_Line_3_Type, init-value=0
        data-element=FD14_Line_4_Confidence, init-value=0
        data-element=FD14_Line_4_Curvature, init-value=0
        data-element=FD14_Line_4_Curvature_Rate, init-value=0
        data-element=FD14_Line_4_End_Range, init-value=0
        data-element=FD14_Line_4_Heading, init-value=0
        data-element=FD14_Line_4_Offset, init-value=0
        data-element=FD14_Line_4_Start_Range, init-value=0
        data-element=FD14_Line_4_Type, init-value=0
        {data-element=FD14_MAC_ADAS_FD_LANES_1, init-value=[rule-based-values={rule=FILL_UNTIL_END, rule-arguments=0}]}
        {data-element=FD14_MAC_ADAS_FD_LANES_2, init-value=[rule-based-values={rule=FILL_UNTIL_END, rule-arguments=0}]}
        data-element=FD14_ParkingManeuverActive, init-value=0
        data-element=FD14_Reserved_for_functional_safety, init-value=0
        data-element=FD14_Segment_1_Confidence, init-value=0
        data-element=FD14_Segment_1_ID, init-value=0
        data-element=FD14_Segment_1_X1, init-value=0
        data-element=FD14_Segment_1_X2, init-value=0
        data-element=FD14_Segment_1_Y1, init-value=0
        data-element=FD14_Segment_1_Y2, init-value=0
        data-element=FD14_Segment_2_Confidence, init-value=0
        data-element=FD14_Segment_2_ID, init-value=0
        data-element=FD14_Segment_2_X1, init-value=0
        data-element=FD14_Segment_2_X2, init-value=0
        data-element=FD14_Segment_2_Y1, init-value=0
        data-element=FD14_Segment_2_Y2, init-value=0
        data-element=FD14_Segment_3_Confidence, init-value=0
        data-element=FD14_Segment_3_ID, init-value=0
        data-element=FD14_Segment_3_X1, init-value=0
        data-element=FD14_Segment_3_X2, init-value=0
        data-element=FD14_Segment_3_Y1, init-value=0
        data-element=FD14_Segment_3_Y2, init-value=0
        data-element=FD14_Segment_4_Confidence, init-value=0
        data-element=FD14_Segment_4_ID, init-value=0
        data-element=FD14_Segment_4_X1, init-value=0
        data-element=FD14_Segment_4_X2, init-value=0
        data-element=FD14_Segment_4_Y1, init-value=0
        data-element=FD14_Segment_4_Y2, init-value=0
        data-element=FD14_Segment_5_Confidence, init-value=0
        data-element=FD14_Segment_5_ID, init-value=0
        data-element=FD14_Segment_5_X1, init-value=0
        data-element=FD14_Segment_5_X2, init-value=0
        data-element=FD14_Segment_5_Y1, init-value=0
        data-element=FD14_Segment_5_Y2, init-value=0
        data-element=FD14_Segment_6_Confidence, init-value=0
        data-element=FD14_Segment_6_ID, init-value=0
        data-element=FD14_Segment_6_X1, init-value=0
        data-element=FD14_Segment_6_X2, init-value=0
        data-element=FD14_Segment_6_Y1, init-value=0
        data-element=FD14_Segment_6_Y2, init-value=0
        data-element=FD14_Segment_7_Confidence, init-value=0
        data-element=FD14_Segment_7_ID, init-value=0
        data-element=FD14_Segment_7_X1, init-value=0
        data-element=FD14_Segment_7_X2, init-value=0
        data-element=FD14_Segment_7_Y1, init-value=0
        data-element=FD14_Segment_7_Y2, init-value=0
        data-element=FD14_Segment_8_Confidence, init-value=0
        data-element=FD14_Segment_8_ID, init-value=0
        data-element=FD14_Segment_8_X1, init-value=0
        data-element=FD14_Segment_8_X2, init-value=0
        data-element=FD14_Segment_8_Y1, init-value=0
        data-element=FD14_Segment_8_Y2, init-value=0
        data-element=FD14_ManoeuvrePhase, init-value=0
        data-element=FD14_ParkingGearShiftReq, init-value=0
        data-element=FD14_PPPA_AccelMax, init-value=0
        data-element=FD14_PPPA_AccelMin, init-value=0
        data-element=FD14_PPPA_DecelMax, init-value=0
        data-element=FD14_PPPA_DecelMin, init-value=0
        data-element=FD14_PPPA_Interface_BSM, init-value=0
        data-element=FD14_PPPA_JerkAccelMax, init-value=0
        data-element=FD14_PPPA_JerkAccelMin, init-value=0
        data-element=FD14_PPPA_JerkDecelMax, init-value=0
        data-element=FD14_PPPA_JerkDecelMin, init-value=0
        data-element=FD14_PPPA_MaxSpeed, init-value=0
        data-element=FD14_PPPA_StandstillRqst, init-value=0
        data-element=FD14_PPPA_TargetDistance, init-value=0
        data-element=FD14_RR_PAM_Brk_RqSts, init-value=0
        data-element=FD14_RR_PAM_Dist, init-value=0
        data-element=FD14_SPM_Lat_Ctrl_RequestSts, init-value=0
        data-element=FD14_TorqueOverlaySteeringReq_SPM, init-value=1024
    9 x require port:
      RpFromSwcSafeFD14Tx: required-interface=IF_ToComSafeFD14Tx
        required-com-specs:
          data-element=FD14_Camera_Status, filter=data-filter-type=ALWAYS, init-value=0
          data-element=FD14_Cntr_ADAS_FD_LANES_1, filter=data-filter-type=ALWAYS, init-value=0
          data-element=FD14_Cntr_ADAS_FD_LANES_2, filter=data-filter-type=ALWAYS, init-value=0
          data-element=FD14_FOD_Confidence, filter=data-filter-type=ALWAYS, init-value=0
          data-element=FD14_Frame_Index_Lanes_1, filter=data-filter-type=ALWAYS, init-value=0
          data-element=FD14_Frame_Index_Lanes_2, filter=data-filter-type=ALWAYS, init-value=0
          data-element=FD14_Health_Front_Object_Detection, filter=data-filter-type=ALWAYS, init-value=0
          data-element=FD14_Health_Lane_Detection, filter=data-filter-type=ALWAYS, init-value=0
          data-element=FD14_Line_1_Confidence, filter=data-filter-type=ALWAYS, init-value=0
          data-element=FD14_Line_1_Curvature, filter=data-filter-type=ALWAYS, init-value=0
          data-element=FD14_Line_1_Curvature_Rate, filter=data-filter-type=ALWAYS, init-value=0
          data-element=FD14_Line_1_End_Range, filter=data-filter-type=ALWAYS, init-value=0
          data-element=FD14_Line_1_Heading, filter=data-filter-type=ALWAYS, init-value=0
          data-element=FD14_Line_1_Offset, filter=data-filter-type=ALWAYS, init-value=0
          data-element=FD14_Line_1_Start_Range, filter=data-filter-type=ALWAYS, init-value=0
          data-element=FD14_Line_1_Type, filter=data-filter-type=ALWAYS, init-value=0
          data-element=FD14_Line_2_Confidence, filter=data-filter-type=ALWAYS, init-value=0
          data-element=FD14_Line_2_Curvature, filter=data-filter-type=ALWAYS, init-value=0
          data-element=FD14_Line_2_Curvature_Rate, filter=data-filter-type=ALWAYS, init-value=0
          data-element=FD14_Line_2_End_Range, filter=data-filter-type=ALWAYS, init-value=0
          data-element=FD14_Line_2_Heading, filter=data-filter-type=ALWAYS, init-value=0
          data-element=FD14_Line_2_Offset, filter=data-filter-type=ALWAYS, init-value=0
          data-element=FD14_Line_2_Start_Range, filter=data-filter-type=ALWAYS, init-value=0
          data-element=FD14_Line_2_Type, filter=data-filter-type=ALWAYS, init-value=0
          data-element=FD14_Line_3_Confidence, filter=data-filter-type=ALWAYS, init-value=0
          data-element=FD14_Line_3_Curvature, filter=data-filter-type=ALWAYS, init-value=0
          data-element=FD14_Line_3_Curvature_Rate, filter=data-filter-type=ALWAYS, init-value=0
          data-element=FD14_Line_3_End_Range, filter=data-filter-type=ALWAYS, init-value=0
          data-element=FD14_Line_3_Heading, filter=data-filter-type=ALWAYS, init-value=0
          data-element=FD14_Line_3_Offset, filter=data-filter-type=ALWAYS, init-value=0
          data-element=FD14_Line_3_Start_Range, filter=data-filter-type=ALWAYS, init-value=0
          data-element=FD14_Line_3_Type, filter=data-filter-type=ALWAYS, init-value=0
          data-element=FD14_Line_4_Confidence, filter=data-filter-type=ALWAYS, init-value=0
          data-element=FD14_Line_4_Curvature, filter=data-filter-type=ALWAYS, init-value=0
          data-element=FD14_Line_4_Curvature_Rate, filter=data-filter-type=ALWAYS, init-value=0
          data-element=FD14_Line_4_End_Range, filter=data-filter-type=ALWAYS, init-value=0
          data-element=FD14_Line_4_Heading, filter=data-filter-type=ALWAYS, init-value=0
          data-element=FD14_Line_4_Offset, filter=data-filter-type=ALWAYS, init-value=0
          data-element=FD14_Line_4_Start_Range, filter=data-filter-type=ALWAYS, init-value=0
          data-element=FD14_Line_4_Type, filter=data-filter-type=ALWAYS, init-value=0
          {data-element=FD14_MAC_ADAS_FD_LANES_1, filter=data-filter-type=ALWAYS, init-value=[rule-based-values={rule=FILL_UNTIL_END, rule-arguments=0}]}
          {data-element=FD14_MAC_ADAS_FD_LANES_2, filter=data-filter-type=ALWAYS, init-value=[rule-based-values={rule=FILL_UNTIL_END, rule-arguments=0}]}
          data-element=FD14_ParkingManeuverActive, filter=data-filter-type=ALWAYS, init-value=0
          data-element=FD14_Reserved_for_functional_safety, filter=data-filter-type=ALWAYS, init-value=0
          data-element=FD14_Segment_1_Confidence, filter=data-filter-type=ALWAYS, init-value=0
          data-element=FD14_Segment_1_ID, filter=data-filter-type=ALWAYS, init-value=0
          data-element=FD14_Segment_1_X1, filter=data-filter-type=ALWAYS, init-value=0
          data-element=FD14_Segment_1_X2, filter=data-filter-type=ALWAYS, init-value=0
          data-element=FD14_Segment_1_Y1, filter=data-filter-type=ALWAYS, init-value=0
          data-element=FD14_Segment_1_Y2, filter=data-filter-type=ALWAYS, init-value=0
          data-element=FD14_Segment_2_Confidence, filter=data-filter-type=ALWAYS, init-value=0
          data-element=FD14_Segment_2_ID, filter=data-filter-type=ALWAYS, init-value=0
          data-element=FD14_Segment_2_X1, filter=data-filter-type=ALWAYS, init-value=0
          data-element=FD14_Segment_2_X2, filter=data-filter-type=ALWAYS, init-value=0
          data-element=FD14_Segment_2_Y1, filter=data-filter-type=ALWAYS, init-value=0
          data-element=FD14_Segment_2_Y2, filter=data-filter-type=ALWAYS, init-value=0
          data-element=FD14_Segment_3_Confidence, filter=data-filter-type=ALWAYS, init-value=0
          data-element=FD14_Segment_3_ID, filter=data-filter-type=ALWAYS, init-value=0
          data-element=FD14_Segment_3_X1, filter=data-filter-type=ALWAYS, init-value=0
          data-element=FD14_Segment_3_X2, filter=data-filter-type=ALWAYS, init-value=0
          data-element=FD14_Segment_3_Y1, filter=data-filter-type=ALWAYS, init-value=0
          data-element=FD14_Segment_3_Y2, filter=data-filter-type=ALWAYS, init-value=0
          data-element=FD14_Segment_4_Confidence, filter=data-filter-type=ALWAYS, init-value=0
          data-element=FD14_Segment_4_ID, filter=data-filter-type=ALWAYS, init-value=0
          data-element=FD14_Segment_4_X1, filter=data-filter-type=ALWAYS, init-value=0
          data-element=FD14_Segment_4_X2, filter=data-filter-type=ALWAYS, init-value=0
          data-element=FD14_Segment_4_Y1, filter=data-filter-type=ALWAYS, init-value=0
          data-element=FD14_Segment_4_Y2, filter=data-filter-type=ALWAYS, init-value=0
          data-element=FD14_Segment_5_Confidence, filter=data-filter-type=ALWAYS, init-value=0
          data-element=FD14_Segment_5_ID, filter=data-filter-type=ALWAYS, init-value=0
          data-element=FD14_Segment_5_X1, filter=data-filter-type=ALWAYS, init-value=0
          data-element=FD14_Segment_5_X2, filter=data-filter-type=ALWAYS, init-value=0
          data-element=FD14_Segment_5_Y1, filter=data-filter-type=ALWAYS, init-value=0
          data-element=FD14_Segment_5_Y2, filter=data-filter-type=ALWAYS, init-value=0
          data-element=FD14_Segment_6_Confidence, filter=data-filter-type=ALWAYS, init-value=0
          data-element=FD14_Segment_6_ID, filter=data-filter-type=ALWAYS, init-value=0
          data-element=FD14_Segment_6_X1, filter=data-filter-type=ALWAYS, init-value=0
          data-element=FD14_Segment_6_X2, filter=data-filter-type=ALWAYS, init-value=0
          data-element=FD14_Segment_6_Y1, filter=data-filter-type=ALWAYS, init-value=0
          data-element=FD14_Segment_6_Y2, filter=data-filter-type=ALWAYS, init-value=0
          data-element=FD14_Segment_7_Confidence, filter=data-filter-type=ALWAYS, init-value=0
          data-element=FD14_Segment_7_ID, filter=data-filter-type=ALWAYS, init-value=0
          data-element=FD14_Segment_7_X1, filter=data-filter-type=ALWAYS, init-value=0
          data-element=FD14_Segment_7_X2, filter=data-filter-type=ALWAYS, init-value=0
          data-element=FD14_Segment_7_Y1, filter=data-filter-type=ALWAYS, init-value=0
          data-element=FD14_Segment_7_Y2, filter=data-filter-type=ALWAYS, init-value=0
          data-element=FD14_Segment_8_Confidence, filter=data-filter-type=ALWAYS, init-value=0
          data-element=FD14_Segment_8_ID, filter=data-filter-type=ALWAYS, init-value=0
          data-element=FD14_Segment_8_X1, filter=data-filter-type=ALWAYS, init-value=0
          data-element=FD14_Segment_8_X2, filter=data-filter-type=ALWAYS, init-value=0
          data-element=FD14_Segment_8_Y1, filter=data-filter-type=ALWAYS, init-value=0
          data-element=FD14_Segment_8_Y2, filter=data-filter-type=ALWAYS, init-value=0
          data-element=FD14_ManoeuvrePhase, filter=data-filter-type=ALWAYS, init-value=0
          data-element=FD14_ParkingGearShiftReq, filter=data-filter-type=ALWAYS, init-value=0
          data-element=FD14_PPPA_AccelMax, filter=data-filter-type=ALWAYS, init-value=0
          data-element=FD14_PPPA_AccelMin, filter=data-filter-type=ALWAYS, init-value=0
          data-element=FD14_PPPA_DecelMax, filter=data-filter-type=ALWAYS, init-value=0
          data-element=FD14_PPPA_DecelMin, filter=data-filter-type=ALWAYS, init-value=0
          data-element=FD14_PPPA_Interface_BSM, filter=data-filter-type=ALWAYS, init-value=0
          data-element=FD14_PPPA_JerkAccelMax, filter=data-filter-type=ALWAYS, init-value=0
          data-element=FD14_PPPA_JerkAccelMin, filter=data-filter-type=ALWAYS, init-value=0
          data-element=FD14_PPPA_JerkDecelMax, filter=data-filter-type=ALWAYS, init-value=0
          data-element=FD14_PPPA_JerkDecelMin, filter=data-filter-type=ALWAYS, init-value=0
          data-element=FD14_PPPA_MaxSpeed, filter=data-filter-type=ALWAYS, init-value=0
          data-element=FD14_PPPA_StandstillRqst, filter=data-filter-type=ALWAYS, init-value=0
          data-element=FD14_PPPA_TargetDistance, filter=data-filter-type=ALWAYS, init-value=0
          data-element=FD14_RR_PAM_Brk_RqSts, filter=data-filter-type=ALWAYS, init-value=0
          data-element=FD14_RR_PAM_Dist, filter=data-filter-type=ALWAYS, init-value=0
          data-element=FD14_SPM_Lat_Ctrl_RequestSts, filter=data-filter-type=ALWAYS, init-value=0
          data-element=FD14_TorqueOverlaySteeringReq_SPM, filter=data-filter-type=ALWAYS, init-value=1024
      RpE2EServices: required-com-specs=[ME_E2E_Check, ME_E2E_Protect], required-interface=IF_E2EServices
      RpAPSMPAOut: nonqueued-receiver-com-spec=data-element=TbAP_APSMPAOut_t, required-interface=IF_APSMPAOut
      RpVCActuatorOut: nonqueued-receiver-com-spec=data-element=TbAP_VCActuatorOut_t, required-interface=IF_VCActuatorOut
      RpSafeGuardCVPAMFDData: nonqueued-receiver-com-spec=data-element=IFOD_Outputs_CVPAMFDData_t, required-interface=IF_CVPAMFDData
      RpSafeGuardCVPAMFDData2: nonqueued-receiver-com-spec=data-element=LMD_Outputs_CVPAMFDData2_t, required-interface=IF_CVPAMFDData2
      RpSafeGuardPAStateOut: nonqueued-receiver-com-spec=data-element=TbAP_PAStateOut_t, required-interface=IF_PAStateOut
      RpSafeGuardVCActuatorOut: nonqueued-receiver-com-spec=data-element=TbAP_VCActuatorOut_t, required-interface=IF_VCActuatorOut
      RpSafeGuardSvsToVCAN: nonqueued-receiver-com-spec=data-element=SvsToVCAN_t, required-interface=IF_SvsToVCAN
    provide port PpToComDbgSafeFD14Tx: provided-interface=IF_ToComDbgSafeFD14Tx
      provided-com-specs:
        data-element=FD14_1_AliveCntr_MCU2_0, init-value=0
        data-element=FD14_1_AliveCntr_MCU2_1, init-value=0
        data-element=FD14_1_AliveCntr_MPU1_0, init-value=0
        data-element=FD14_1_OsRegMCU_ADFSR, init-value=0
        data-element=FD14_1_OsRegMCU_AIFSR, init-value=0
        data-element=FD14_1_OsRegMCU_DFAR, init-value=0
        data-element=FD14_1_OsRegMCU_DFSR, init-value=0
        data-element=FD14_1_OsRegMCU_IFAR, init-value=0
        data-element=FD14_1_OsRegMCU_IFSR, init-value=0
        data-element=FD14_1_OsRegMCU_Link, init-value=0
        data-element=FD14_1_OsRegMCU_SPSR, init-value=0
        data-element=FD14_1_OsRegMCU_Stack{0..9}, init-value=0
        data-element=FD14_1_SSM_SystemStateReq, init-value=0
        data-element=FD14_1_TimeSincePowerON, init-value=0
        data-element=FD14_1_Err_FaultInfo_MCU1_0, init-value=0
        data-element=FD14_1_Err_FaultInfo_MCU2_1, init-value=0
        data-element=FD14_1_Err_FaultInfo_MPU1_0, init-value=0
        data-element=FD14_1_Err_FaultNum_MCU1_0, init-value=0
        data-element=FD14_1_Err_FaultNum_MCU2_0, init-value=0
        data-element=FD14_1_Err_FaultNum_MCU2_1, init-value=0
        data-element=FD14_1_Err_FaultNum_MPU1_0, init-value=0
        data-element=FD14_1_ErrFaultInfo_MCU2_0, init-value=0
        data-element=FD14_1_Reserved_MCU1_0, init-value=0
        data-element=FD14_1_Reserved_MCU2_0, init-value=0
        data-element=FD14_1_Reserved_MCU2_1, init-value=0
        data-element=FD14_1_Reserved_MPU1_0, init-value=0
        data-element=FD14_1_SDL_Fault_MCU1_0, init-value=0
        data-element=FD14_1_SSM_FltData1_MCU1_0, init-value=0
        data-element=FD14_1_SSM_FltData{10..18}_MCU1_0, init-value=0
        data-element=FD14_1_SSM_FltData{2..9}_MCU1_0, init-value=0
        data-element=FD14_1_WDG_Error_ID_MCU1_0, init-value=0
        data-element=FD14_1_Hook_actTsk_MCU1_0, init-value=0
        data-element=FD14_1_Hook_DtErr_MCU1_0, init-value=0
        data-element=FD14_1_Hook_Error_MCU1_0, init-value=0
        data-element=FD14_1_Hook_fatalErr_MCU1_0, init-value=0
        data-element=FD14_1_Hook_PresentPtr_MCU1_0, init-value=0
        data-element=FD14_1_Hook_Reserved_MCU1_0, init-value=0
        data-element=FD14_1_Hook_Service_MCU1_0, init-value=0
        data-element=FD14_1_Hook_Type_MCU1_0, init-value=0
    8 x require port:
      RpErrFltMcu2_0: nonqueued-receiver-com-spec{data-element=Error_Fault_MCU2_0_t, filter=data-filter-type=ALWAYS}, required-interface=IF_ErrFltMcu2_0
      RpErrFltMcu2_1: nonqueued-receiver-com-spec{data-element=Error_Fault_MCU2_1_t, filter=data-filter-type=ALWAYS}, required-interface=IF_ErrFltMcu2_1
      RpErrFltMpu1_0: nonqueued-receiver-com-spec{data-element=Error_Fault_MPU1_0_t, filter=data-filter-type=ALWAYS}, required-interface=IF_ErrFltMpu1_0
      R_SystemState: nonqueued-receiver-com-spec=data-element=SystemState, required-interface=P_SystemState_SR
      RpKeepAliveResponse: nonqueued-receiver-com-spec{data-element=KeepAliveResponse_t, filter=data-filter-type=ALWAYS, init-value=fields=[FrameID_u32:0, ResponseCode_u8:0]}, required-interface=IF_KeepAliveResponse
      RpWdgCheckpointStatusMcu2_0: nonqueued-receiver-com-spec{data-element=WdgCheckpointStatus_t, filter=data-filter-type=ALWAYS}, required-interface=IF_WdgCheckpointStatus
      RpWdgCheckpointStatusMcu2_1: nonqueued-receiver-com-spec{data-element=WdgCheckpointStatus_t, filter=data-filter-type=ALWAYS}, required-interface=IF_WdgCheckpointStatus
      RpWdgCheckpointStatusMpu1_0: nonqueued-receiver-com-spec{data-element=WdgCheckpointStatus_t, filter=data-filter-type=ALWAYS}, required-interface=IF_WdgCheckpointStatus
    behavior SWC_SafeVCANTx_InternalBehavior
      init event SWC_SafeVCANTx_InitEvent: start-on-event=RE_SafeVCANTx_Init
      timing event TMT_RE_SafeVCANTx_Main: start-on-event=RE_SafeVCANTx_Main, period=0.01
      runnable RE_SafeVCANTx_Init
      runnable RE_SafeVCANTx_Main
        data-receive-point-by-arguments:
          270 x access:
            REC_RpFromSwcSafeFD02Tx_AUXCamsRQSts: accessed-variable=RpFromSwcSafeFD02Tx.AUXCamsRQSts
            REC_RpFromSwcSafeFD02Tx_Alert_CHF: accessed-variable=RpFromSwcSafeFD02Tx.Alert_CHF
            REC_RpFromSwcSafeFD02Tx_Alert_CHR: accessed-variable=RpFromSwcSafeFD02Tx.Alert_CHR
            REC_RpFromSwcSafeFD02Tx_Alert_LHF: accessed-variable=RpFromSwcSafeFD02Tx.Alert_LHF
            REC_RpFromSwcSafeFD02Tx_Alert_LHR: accessed-variable=RpFromSwcSafeFD02Tx.Alert_LHR
            REC_RpFromSwcSafeFD02Tx_Alert_RHF: accessed-variable=RpFromSwcSafeFD02Tx.Alert_RHF
            REC_RpFromSwcSafeFD02Tx_Alert_RHR: accessed-variable=RpFromSwcSafeFD02Tx.Alert_RHR
            REC_RpFromSwcSafeFD02Tx_ChimeActivation_LHF: accessed-variable=RpFromSwcSafeFD02Tx.ChimeActivation_LHF
            REC_RpFromSwcSafeFD02Tx_ChimeActivation_LHR: accessed-variable=RpFromSwcSafeFD02Tx.ChimeActivation_LHR
            REC_RpFromSwcSafeFD02Tx_ChimeActivation_RHF: accessed-variable=RpFromSwcSafeFD02Tx.ChimeActivation_RHF
            REC_RpFromSwcSafeFD02Tx_ChimeActivation_RHR: accessed-variable=RpFromSwcSafeFD02Tx.ChimeActivation_RHR
            REC_RpFromSwcSafeFD02Tx_DisplayView2: accessed-variable=RpFromSwcSafeFD02Tx.DisplayView2
            REC_RpFromSwcSafeFD02Tx_FT_PAM_LedControlSts: accessed-variable=RpFromSwcSafeFD02Tx.FT_PAM_LedControlSts
            REC_RpFromSwcSafeFD02Tx_FrontSensorSts: accessed-variable=RpFromSwcSafeFD02Tx.FrontSensorSts
            REC_RpFromSwcSafeFD02Tx_Graphic_CHF: accessed-variable=RpFromSwcSafeFD02Tx.Graphic_CHF
            REC_RpFromSwcSafeFD02Tx_Graphic_CHR: accessed-variable=RpFromSwcSafeFD02Tx.Graphic_CHR
            REC_RpFromSwcSafeFD02Tx_Graphic_LHF: accessed-variable=RpFromSwcSafeFD02Tx.Graphic_LHF
            REC_RpFromSwcSafeFD02Tx_Graphic_LHR: accessed-variable=RpFromSwcSafeFD02Tx.Graphic_LHR
            REC_RpFromSwcSafeFD02Tx_Graphic_RHF: accessed-variable=RpFromSwcSafeFD02Tx.Graphic_RHF
            REC_RpFromSwcSafeFD02Tx_Graphic_RHR: accessed-variable=RpFromSwcSafeFD02Tx.Graphic_RHR
            REC_RpFromSwcSafeFD02Tx_HMICode: accessed-variable=RpFromSwcSafeFD02Tx.HMICode
            REC_RpFromSwcSafeFD02Tx_ImageDefeatRQSts: accessed-variable=RpFromSwcSafeFD02Tx.ImageDefeatRQSts
            REC_RpFromSwcSafeFD02Tx_MoreCamsRQSts: accessed-variable=RpFromSwcSafeFD02Tx.MoreCamsRQSts
            REC_RpFromSwcSafeFD02Tx_PAMSystemFault: accessed-variable=RpFromSwcSafeFD02Tx.PAMSystemFault
            REC_RpFromSwcSafeFD02Tx_PAM_CHIME_REP_RATESts: accessed-variable=RpFromSwcSafeFD02Tx.PAM_CHIME_REP_RATESts
            REC_RpFromSwcSafeFD02Tx_PAM_CHIME_TYPE: accessed-variable=RpFromSwcSafeFD02Tx.PAM_CHIME_TYPE
            REC_RpFromSwcSafeFD02Tx_PAM_LedControlSts: accessed-variable=RpFromSwcSafeFD02Tx.PAM_LedControlSts
            REC_RpFromSwcSafeFD02Tx_PAM_Off_Status: accessed-variable=RpFromSwcSafeFD02Tx.PAM_Off_Status
            REC_RpFromSwcSafeFD02Tx_PAM_Off_Status_2BT: accessed-variable=RpFromSwcSafeFD02Tx.PAM_Off_Status_2BT
            REC_RpFromSwcSafeFD02Tx_PAM_PopUpRqst: accessed-variable=RpFromSwcSafeFD02Tx.PAM_PopUpRqst
            REC_RpFromSwcSafeFD02Tx_PAM_Volume: accessed-variable=RpFromSwcSafeFD02Tx.PAM_Volume
            REC_RpFromSwcSafeFD02Tx_PPPA_TurnIndicatorRqst: accessed-variable=RpFromSwcSafeFD02Tx.PPPA_TurnIndicatorRqst
            REC_RpFromSwcSafeFD02Tx_ParkingManeuverActive: accessed-variable=RpFromSwcSafeFD02Tx.ParkingManeuverActive
            REC_RpFromSwcSafeFD02Tx_RR_PAM_Brk_RqSts: accessed-variable=RpFromSwcSafeFD02Tx.RR_PAM_Brk_RqSts
            REC_RpFromSwcSafeFD02Tx_RR_PAM_Dist: accessed-variable=RpFromSwcSafeFD02Tx.RR_PAM_Dist
            REC_RpFromSwcSafeFD02Tx_RR_PAM_StopControlSts: accessed-variable=RpFromSwcSafeFD02Tx.RR_PAM_StopControlSts
            REC_RpFromSwcSafeFD02Tx_RearSensorSts: accessed-variable=RpFromSwcSafeFD02Tx.RearSensorSts
            REC_RpFromSwcSafeFD02Tx_SPMControlSts: accessed-variable=RpFromSwcSafeFD02Tx.SPMControlSts
            REC_RpFromSwcSafeFD02Tx_SPMFailSts: accessed-variable=RpFromSwcSafeFD02Tx.SPMFailSts
            REC_RpFromSwcSafeFD02Tx_SPMSystemFault: accessed-variable=RpFromSwcSafeFD02Tx.SPMSystemFault
            REC_RpFromSwcSafeFD02Tx_SPM_LedControlSts: accessed-variable=RpFromSwcSafeFD02Tx.SPM_LedControlSts
            REC_RpFromSwcSafeFD02Tx_SPM_Screen_Rqst: accessed-variable=RpFromSwcSafeFD02Tx.SPM_Screen_Rqst
            REC_RpFromSwcSafeFD02Tx_TRSC_LED_Stat: accessed-variable=RpFromSwcSafeFD02Tx.TRSC_LED_Stat
            REC_RpCVPAMFDData_IFOD_Outputs_CVPAMFDData_t: accessed-variable=RpCVPAMFDData.IFOD_Outputs_CVPAMFDData_t
            REC_RpCVPAMFDData2_LMD_Outputs_CVPAMFDData2_t: accessed-variable=RpCVPAMFDData2.LMD_Outputs_CVPAMFDData2_t
            REC_RpDriveAssistStatOut_TbAP_DriveAssistStatOut_t: accessed-variable=RpDriveAssistStatOut.TbAP_DriveAssistStatOut_t
            REC_RpFPAWarnOut_TbAP_FPAWarnOut_t: accessed-variable=RpFPAWarnOut.TbAP_FPAWarnOut_t
            REC_RpPAStateOut_TbAP_PAStateOut_t: accessed-variable=RpPAStateOut.TbAP_PAStateOut_t
            REC_RpRPAWarnOut_TbAP_RPAWarnOut_t: accessed-variable=RpRPAWarnOut.TbAP_RPAWarnOut_t
            REC_RpSvsToVCAN_SvsToVCAN_t: accessed-variable=RpSvsToVCAN.SvsToVCAN_t
            REC_RpTRSC_ME_VehOut_TRSC_t: accessed-variable=RpTRSC.ME_VehOut_TRSC_t
            REC_RpTbAPDebugOut_TbAP_DebugOut: accessed-variable=RpTbAPDebugOut.TbAP_DebugOut
            REC_RpTbAPSMPAOut_TbAP_SMPAInternalOut_t: accessed-variable=RpTbAPSMPAOut.TbAP_SMPAInternalOut_t
            REC_RpTbFAArbiterOutput_TbFA_ArbiterOutput_t: accessed-variable=RpTbFAArbiterOutput.TbFA_ArbiterOutput_t
            REC_RpFromSwcSafeFD14Tx_FD14_ManoeuvrePhase: accessed-variable=RpFromSwcSafeFD14Tx.FD14_ManoeuvrePhase
            REC_RpFromSwcSafeFD14Tx_FD14_PPPA_AccelMax: accessed-variable=RpFromSwcSafeFD14Tx.FD14_PPPA_AccelMax
            REC_RpFromSwcSafeFD14Tx_FD14_PPPA_AccelMin: accessed-variable=RpFromSwcSafeFD14Tx.FD14_PPPA_AccelMin
            REC_RpFromSwcSafeFD14Tx_FD14_PPPA_DecelMax: accessed-variable=RpFromSwcSafeFD14Tx.FD14_PPPA_DecelMax
            REC_RpFromSwcSafeFD14Tx_FD14_PPPA_DecelMin: accessed-variable=RpFromSwcSafeFD14Tx.FD14_PPPA_DecelMin
            REC_RpFromSwcSafeFD14Tx_FD14_PPPA_Interface_BSM: accessed-variable=RpFromSwcSafeFD14Tx.FD14_PPPA_Interface_BSM
            REC_RpFromSwcSafeFD14Tx_FD14_PPPA_JerkAccelMax: accessed-variable=RpFromSwcSafeFD14Tx.FD14_PPPA_JerkAccelMax
            REC_RpFromSwcSafeFD14Tx_FD14_PPPA_JerkAccelMin: accessed-variable=RpFromSwcSafeFD14Tx.FD14_PPPA_JerkAccelMin
            REC_RpFromSwcSafeFD14Tx_FD14_PPPA_JerkDecelMax: accessed-variable=RpFromSwcSafeFD14Tx.FD14_PPPA_JerkDecelMax
            REC_RpFromSwcSafeFD14Tx_FD14_PPPA_JerkDecelMin: accessed-variable=RpFromSwcSafeFD14Tx.FD14_PPPA_JerkDecelMin
            REC_RpFromSwcSafeFD14Tx_FD14_PPPA_MaxSpeed: accessed-variable=RpFromSwcSafeFD14Tx.FD14_PPPA_MaxSpeed
            REC_RpFromSwcSafeFD14Tx_FD14_PPPA_StandstillRqst: accessed-variable=RpFromSwcSafeFD14Tx.FD14_PPPA_StandstillRqst
            REC_RpFromSwcSafeFD14Tx_FD14_PPPA_TargetDistance: accessed-variable=RpFromSwcSafeFD14Tx.FD14_PPPA_TargetDistance
            REC_RpFromSwcSafeFD14Tx_FD14_ParkingGearShiftReq: accessed-variable=RpFromSwcSafeFD14Tx.FD14_ParkingGearShiftReq
            REC_RpFromSwcSafeFD14Tx_FD14_RR_PAM_Brk_RqSts: accessed-variable=RpFromSwcSafeFD14Tx.FD14_RR_PAM_Brk_RqSts
            REC_RpFromSwcSafeFD14Tx_FD14_RR_PAM_Dist: accessed-variable=RpFromSwcSafeFD14Tx.FD14_RR_PAM_Dist
            REC_RpFromSwcSafeFD14Tx_FD14_SPM_Lat_Ctrl_RequestSts: accessed-variable=RpFromSwcSafeFD14Tx.FD14_SPM_Lat_Ctrl_RequestSts
            REC_RpFromSwcSafeFD14Tx_FD14_TorqueOverlaySteeringReq_SPM: accessed-variable=RpFromSwcSafeFD14Tx.FD14_TorqueOverlaySteeringReq_SPM
            REC_RpAPSMPAOut_TbAP_APSMPAOut_t: accessed-variable=RpAPSMPAOut.TbAP_APSMPAOut_t
            REC_RpVCActuatorOut_TbAP_VCActuatorOut_t: accessed-variable=RpVCActuatorOut.TbAP_VCActuatorOut_t
            REC_RpSafeGaurdCVPAMFDData2_LMD_Outputs_CVPAMFDData2_t: accessed-variable=RpSafeGuardCVPAMFDData2.LMD_Outputs_CVPAMFDData2_t
            REC_RpSafeGuardCVPAMFDData_IFOD_Outputs_CVPAMFDData_t: accessed-variable=RpSafeGuardCVPAMFDData.IFOD_Outputs_CVPAMFDData_t
            REC_RpFromSwcSafeFD14Tx_FD14_Camera_Status: accessed-variable=RpFromSwcSafeFD14Tx.FD14_Camera_Status
            REC_RpFromSwcSafeFD14Tx_FD14_Cntr_ADAS_FD_LANES_1: accessed-variable=RpFromSwcSafeFD14Tx.FD14_Cntr_ADAS_FD_LANES_1
            REC_RpFromSwcSafeFD14Tx_FD14_Cntr_ADAS_FD_LANES_2: accessed-variable=RpFromSwcSafeFD14Tx.FD14_Cntr_ADAS_FD_LANES_2
            REC_RpFromSwcSafeFD14Tx_FD14_FOD_Confidence: accessed-variable=RpFromSwcSafeFD14Tx.FD14_FOD_Confidence
            REC_RpFromSwcSafeFD14Tx_FD14_Frame_Index_Lanes_1: accessed-variable=RpFromSwcSafeFD14Tx.FD14_Frame_Index_Lanes_1
            REC_RpFromSwcSafeFD14Tx_FD14_Frame_Index_Lanes_2: accessed-variable=RpFromSwcSafeFD14Tx.FD14_Frame_Index_Lanes_2
            REC_RpFromSwcSafeFD14Tx_FD14_Health_Front_Object_Detection: accessed-variable=RpFromSwcSafeFD14Tx.FD14_Health_Front_Object_Detection
            REC_RpFromSwcSafeFD14Tx_FD14_Health_Lane_Detection: accessed-variable=RpFromSwcSafeFD14Tx.FD14_Health_Lane_Detection
            REC_RpFromSwcSafeFD14Tx_FD14_Line_1_Confidence: accessed-variable=RpFromSwcSafeFD14Tx.FD14_Line_1_Confidence
            REC_RpFromSwcSafeFD14Tx_FD14_Line_1_Curvature: accessed-variable=RpFromSwcSafeFD14Tx.FD14_Line_1_Curvature
            REC_RpFromSwcSafeFD14Tx_FD14_Line_1_Curvature_Rate: accessed-variable=RpFromSwcSafeFD14Tx.FD14_Line_1_Curvature_Rate
            REC_RpFromSwcSafeFD14Tx_FD14_Line_1_End_Range: accessed-variable=RpFromSwcSafeFD14Tx.FD14_Line_1_End_Range
            REC_RpFromSwcSafeFD14Tx_FD14_Line_1_Heading: accessed-variable=RpFromSwcSafeFD14Tx.FD14_Line_1_Heading
            REC_RpFromSwcSafeFD14Tx_FD14_Line_1_Offset: accessed-variable=RpFromSwcSafeFD14Tx.FD14_Line_1_Offset
            REC_RpFromSwcSafeFD14Tx_FD14_Line_1_Start_Range: accessed-variable=RpFromSwcSafeFD14Tx.FD14_Line_1_Start_Range
            REC_RpFromSwcSafeFD14Tx_FD14_Line_1_Type: accessed-variable=RpFromSwcSafeFD14Tx.FD14_Line_1_Type
            REC_RpFromSwcSafeFD14Tx_FD14_Line_2_Confidence: accessed-variable=RpFromSwcSafeFD14Tx.FD14_Line_2_Confidence
            REC_RpFromSwcSafeFD14Tx_FD14_Line_2_Curvature: accessed-variable=RpFromSwcSafeFD14Tx.FD14_Line_2_Curvature
            REC_RpFromSwcSafeFD14Tx_FD14_Line_2_Curvature_Rate: accessed-variable=RpFromSwcSafeFD14Tx.FD14_Line_2_Curvature_Rate
            REC_RpFromSwcSafeFD14Tx_FD14_Line_2_End_Range: accessed-variable=RpFromSwcSafeFD14Tx.FD14_Line_2_End_Range
            REC_RpFromSwcSafeFD14Tx_FD14_Line_2_Heading: accessed-variable=RpFromSwcSafeFD14Tx.FD14_Line_2_Heading
            REC_RpFromSwcSafeFD14Tx_FD14_Line_2_Offset: accessed-variable=RpFromSwcSafeFD14Tx.FD14_Line_2_Offset
            REC_RpFromSwcSafeFD14Tx_FD14_Line_2_Start_Range: accessed-variable=RpFromSwcSafeFD14Tx.FD14_Line_2_Start_Range
            REC_RpFromSwcSafeFD14Tx_FD14_Line_2_Type: accessed-variable=RpFromSwcSafeFD14Tx.FD14_Line_2_Type
            REC_RpFromSwcSafeFD14Tx_FD14_Line_3_Confidence: accessed-variable=RpFromSwcSafeFD14Tx.FD14_Line_3_Confidence
            REC_RpFromSwcSafeFD14Tx_FD14_Line_3_Curvature: accessed-variable=RpFromSwcSafeFD14Tx.FD14_Line_3_Curvature
            REC_RpFromSwcSafeFD14Tx_FD14_Line_3_Curvature_Rate: accessed-variable=RpFromSwcSafeFD14Tx.FD14_Line_3_Curvature_Rate
            REC_RpFromSwcSafeFD14Tx_FD14_Line_3_End_Range: accessed-variable=RpFromSwcSafeFD14Tx.FD14_Line_3_End_Range
            REC_RpFromSwcSafeFD14Tx_FD14_Line_3_Heading: accessed-variable=RpFromSwcSafeFD14Tx.FD14_Line_3_Heading
            REC_RpFromSwcSafeFD14Tx_FD14_Line_3_Offset: accessed-variable=RpFromSwcSafeFD14Tx.FD14_Line_3_Offset
            REC_RpFromSwcSafeFD14Tx_FD14_Line_3_Start_Range: accessed-variable=RpFromSwcSafeFD14Tx.FD14_Line_3_Start_Range
            REC_RpFromSwcSafeFD14Tx_FD14_Line_3_Type: accessed-variable=RpFromSwcSafeFD14Tx.FD14_Line_3_Type
            REC_RpFromSwcSafeFD14Tx_FD14_Line_4_Confidence: accessed-variable=RpFromSwcSafeFD14Tx.FD14_Line_4_Confidence
            REC_RpFromSwcSafeFD14Tx_FD14_Line_4_Curvature: accessed-variable=RpFromSwcSafeFD14Tx.FD14_Line_4_Curvature
            REC_RpFromSwcSafeFD14Tx_FD14_Line_4_Curvature_Rate: accessed-variable=RpFromSwcSafeFD14Tx.FD14_Line_4_Curvature_Rate
            REC_RpFromSwcSafeFD14Tx_FD14_Line_4_End_Range: accessed-variable=RpFromSwcSafeFD14Tx.FD14_Line_4_End_Range
            REC_RpFromSwcSafeFD14Tx_FD14_Line_4_Heading: accessed-variable=RpFromSwcSafeFD14Tx.FD14_Line_4_Heading
            REC_RpFromSwcSafeFD14Tx_FD14_Line_4_Offset: accessed-variable=RpFromSwcSafeFD14Tx.FD14_Line_4_Offset
            REC_RpFromSwcSafeFD14Tx_FD14_Line_4_Start_Range: accessed-variable=RpFromSwcSafeFD14Tx.FD14_Line_4_Start_Range
            REC_RpFromSwcSafeFD14Tx_FD14_Line_4_Type: accessed-variable=RpFromSwcSafeFD14Tx.FD14_Line_4_Type
            REC_RpFromSwcSafeFD14Tx_FD14_MAC_ADAS_FD_LANES_1: accessed-variable=RpFromSwcSafeFD14Tx.FD14_MAC_ADAS_FD_LANES_1
            REC_RpFromSwcSafeFD14Tx_FD14_MAC_ADAS_FD_LANES_2: accessed-variable=RpFromSwcSafeFD14Tx.FD14_MAC_ADAS_FD_LANES_2
            REC_RpFromSwcSafeFD14Tx_FD14_ParkingManeuverActive: accessed-variable=RpFromSwcSafeFD14Tx.FD14_ParkingManeuverActive
            REC_RpFromSwcSafeFD14Tx_FD14_Reserved_for_functional_safety: accessed-variable=RpFromSwcSafeFD14Tx.FD14_Reserved_for_functional_safety
            REC_RpFromSwcSafeFD14Tx_FD14_Segment_1_Confidence: accessed-variable=RpFromSwcSafeFD14Tx.FD14_Segment_1_Confidence
            REC_RpFromSwcSafeFD14Tx_FD14_Segment_1_ID: accessed-variable=RpFromSwcSafeFD14Tx.FD14_Segment_1_ID
            REC_RpFromSwcSafeFD14Tx_FD14_Segment_1_X1: accessed-variable=RpFromSwcSafeFD14Tx.FD14_Segment_1_X1
            REC_RpFromSwcSafeFD14Tx_FD14_Segment_1_X2: accessed-variable=RpFromSwcSafeFD14Tx.FD14_Segment_1_X2
            REC_RpFromSwcSafeFD14Tx_FD14_Segment_1_Y1: accessed-variable=RpFromSwcSafeFD14Tx.FD14_Segment_1_Y1
            REC_RpFromSwcSafeFD14Tx_FD14_Segment_1_Y2: accessed-variable=RpFromSwcSafeFD14Tx.FD14_Segment_1_Y2
            REC_RpFromSwcSafeFD14Tx_FD14_Segment_2_Confidence: accessed-variable=RpFromSwcSafeFD14Tx.FD14_Segment_2_Confidence
            REC_RpFromSwcSafeFD14Tx_FD14_Segment_2_ID: accessed-variable=RpFromSwcSafeFD14Tx.FD14_Segment_2_ID
            REC_RpFromSwcSafeFD14Tx_FD14_Segment_2_X1: accessed-variable=RpFromSwcSafeFD14Tx.FD14_Segment_2_X1
            REC_RpFromSwcSafeFD14Tx_FD14_Segment_2_X2: accessed-variable=RpFromSwcSafeFD14Tx.FD14_Segment_2_X2
            REC_RpFromSwcSafeFD14Tx_FD14_Segment_2_Y1: accessed-variable=RpFromSwcSafeFD14Tx.FD14_Segment_2_Y1
            REC_RpFromSwcSafeFD14Tx_FD14_Segment_2_Y2: accessed-variable=RpFromSwcSafeFD14Tx.FD14_Segment_2_Y2
            REC_RpFromSwcSafeFD14Tx_FD14_Segment_3_Confidence: accessed-variable=RpFromSwcSafeFD14Tx.FD14_Segment_3_Confidence
            REC_RpFromSwcSafeFD14Tx_FD14_Segment_3_ID: accessed-variable=RpFromSwcSafeFD14Tx.FD14_Segment_3_ID
            REC_RpFromSwcSafeFD14Tx_FD14_Segment_3_X1: accessed-variable=RpFromSwcSafeFD14Tx.FD14_Segment_3_X1
            REC_RpFromSwcSafeFD14Tx_FD14_Segment_3_X2: accessed-variable=RpFromSwcSafeFD14Tx.FD14_Segment_3_X2
            REC_RpFromSwcSafeFD14Tx_FD14_Segment_3_Y1: accessed-variable=RpFromSwcSafeFD14Tx.FD14_Segment_3_Y1
            REC_RpFromSwcSafeFD14Tx_FD14_Segment_3_Y2: accessed-variable=RpFromSwcSafeFD14Tx.FD14_Segment_3_Y2
            REC_RpFromSwcSafeFD14Tx_FD14_Segment_4_Confidence: accessed-variable=RpFromSwcSafeFD14Tx.FD14_Segment_4_Confidence
            REC_RpFromSwcSafeFD14Tx_FD14_Segment_4_ID: accessed-variable=RpFromSwcSafeFD14Tx.FD14_Segment_4_ID
            REC_RpFromSwcSafeFD14Tx_FD14_Segment_4_X1: accessed-variable=RpFromSwcSafeFD14Tx.FD14_Segment_4_X1
            REC_RpFromSwcSafeFD14Tx_FD14_Segment_4_X2: accessed-variable=RpFromSwcSafeFD14Tx.FD14_Segment_4_X2
            REC_RpFromSwcSafeFD14Tx_FD14_Segment_4_Y1: accessed-variable=RpFromSwcSafeFD14Tx.FD14_Segment_4_Y1
            REC_RpFromSwcSafeFD14Tx_FD14_Segment_4_Y2: accessed-variable=RpFromSwcSafeFD14Tx.FD14_Segment_4_Y2
            REC_RpFromSwcSafeFD14Tx_FD14_Segment_5_Confidence: accessed-variable=RpFromSwcSafeFD14Tx.FD14_Segment_5_Confidence
            REC_RpFromSwcSafeFD14Tx_FD14_Segment_5_ID: accessed-variable=RpFromSwcSafeFD14Tx.FD14_Segment_5_ID
            REC_RpFromSwcSafeFD14Tx_FD14_Segment_5_X1: accessed-variable=RpFromSwcSafeFD14Tx.FD14_Segment_5_X1
            REC_RpFromSwcSafeFD14Tx_FD14_Segment_5_X2: accessed-variable=RpFromSwcSafeFD14Tx.FD14_Segment_5_X2
            REC_RpFromSwcSafeFD14Tx_FD14_Segment_5_Y1: accessed-variable=RpFromSwcSafeFD14Tx.FD14_Segment_5_Y1
            REC_RpFromSwcSafeFD14Tx_FD14_Segment_5_Y2: accessed-variable=RpFromSwcSafeFD14Tx.FD14_Segment_5_Y2
            REC_RpFromSwcSafeFD14Tx_FD14_Segment_6_Confidence: accessed-variable=RpFromSwcSafeFD14Tx.FD14_Segment_6_Confidence
            REC_RpFromSwcSafeFD14Tx_FD14_Segment_6_ID: accessed-variable=RpFromSwcSafeFD14Tx.FD14_Segment_6_ID
            REC_RpFromSwcSafeFD14Tx_FD14_Segment_6_X1: accessed-variable=RpFromSwcSafeFD14Tx.FD14_Segment_6_X1
            REC_RpFromSwcSafeFD14Tx_FD14_Segment_6_X2: accessed-variable=RpFromSwcSafeFD14Tx.FD14_Segment_6_X2
            REC_RpFromSwcSafeFD14Tx_FD14_Segment_6_Y1: accessed-variable=RpFromSwcSafeFD14Tx.FD14_Segment_6_Y1
            REC_RpFromSwcSafeFD14Tx_FD14_Segment_6_Y2: accessed-variable=RpFromSwcSafeFD14Tx.FD14_Segment_6_Y2
            REC_RpFromSwcSafeFD14Tx_FD14_Segment_7_Confidence: accessed-variable=RpFromSwcSafeFD14Tx.FD14_Segment_7_Confidence
            REC_RpFromSwcSafeFD14Tx_FD14_Segment_7_ID: accessed-variable=RpFromSwcSafeFD14Tx.FD14_Segment_7_ID
            REC_RpFromSwcSafeFD14Tx_FD14_Segment_7_X1: accessed-variable=RpFromSwcSafeFD14Tx.FD14_Segment_7_X1
            REC_RpFromSwcSafeFD14Tx_FD14_Segment_7_X2: accessed-variable=RpFromSwcSafeFD14Tx.FD14_Segment_7_X2
            REC_RpFromSwcSafeFD14Tx_FD14_Segment_7_Y1: accessed-variable=RpFromSwcSafeFD14Tx.FD14_Segment_7_Y1
            REC_RpFromSwcSafeFD14Tx_FD14_Segment_7_Y2: accessed-variable=RpFromSwcSafeFD14Tx.FD14_Segment_7_Y2
            REC_RpFromSwcSafeFD14Tx_FD14_Segment_8_Confidence: accessed-variable=RpFromSwcSafeFD14Tx.FD14_Segment_8_Confidence
            REC_RpFromSwcSafeFD14Tx_FD14_Segment_8_ID: accessed-variable=RpFromSwcSafeFD14Tx.FD14_Segment_8_ID
            REC_RpFromSwcSafeFD14Tx_FD14_Segment_8_X1: accessed-variable=RpFromSwcSafeFD14Tx.FD14_Segment_8_X1
            REC_RpFromSwcSafeFD14Tx_FD14_Segment_8_X2: accessed-variable=RpFromSwcSafeFD14Tx.FD14_Segment_8_X2
            REC_RpFromSwcSafeFD14Tx_FD14_Segment_8_Y1: accessed-variable=RpFromSwcSafeFD14Tx.FD14_Segment_8_Y1
            REC_RpFromSwcSafeFD14Tx_FD14_Segment_8_Y2: accessed-variable=RpFromSwcSafeFD14Tx.FD14_Segment_8_Y2
            REC_RpSafeGuardPAStateOut_TbAP_PAStateOut_t: accessed-variable=RpSafeGuardPAStateOut.TbAP_PAStateOut_t
            REC_RpSafeGuardVCActuatorOut_TbAP_VCActuatorOut_t: accessed-variable=RpSafeGuardVCActuatorOut.TbAP_VCActuatorOut_t
            REC_RpSafeGaurdSvsToVCAN_SvsToVCAN_t: accessed-variable=RpSafeGuardSvsToVCAN.SvsToVCAN_t
            REC_RpFromSwcSafeFD02Tx_Camera_Status: accessed-variable=RpFromSwcSafeFD02Tx.Camera_Status
            REC_RpFromSwcSafeFD02Tx_Cntr_ADAS_FD_LANES_1: accessed-variable=RpFromSwcSafeFD02Tx.Cntr_ADAS_FD_LANES_1
            REC_RpFromSwcSafeFD02Tx_Cntr_ADAS_FD_LANES_2: accessed-variable=RpFromSwcSafeFD02Tx.Cntr_ADAS_FD_LANES_2
            REC_RpFromSwcSafeFD02Tx_FOD_Confidence: accessed-variable=RpFromSwcSafeFD02Tx.FOD_Confidence
            REC_RpFromSwcSafeFD02Tx_Frame_Index_Lanes_1: accessed-variable=RpFromSwcSafeFD02Tx.Frame_Index_Lanes_1
            REC_RpFromSwcSafeFD02Tx_Frame_Index_Lanes_2: accessed-variable=RpFromSwcSafeFD02Tx.Frame_Index_Lanes_2
            REC_RpFromSwcSafeFD02Tx_Health_Front_Object_Detection: accessed-variable=RpFromSwcSafeFD02Tx.Health_Front_Object_Detection
            REC_RpFromSwcSafeFD02Tx_Health_Lane_Detection: accessed-variable=RpFromSwcSafeFD02Tx.Health_Lane_Detection
            REC_RpFromSwcSafeFD02Tx_Line_1_Confidence: accessed-variable=RpFromSwcSafeFD02Tx.Line_1_Confidence
            REC_RpFromSwcSafeFD02Tx_Line_1_Curvature: accessed-variable=RpFromSwcSafeFD02Tx.Line_1_Curvature
            REC_RpFromSwcSafeFD02Tx_Line_1_Curvature_Rate: accessed-variable=RpFromSwcSafeFD02Tx.Line_1_Curvature_Rate
            REC_RpFromSwcSafeFD02Tx_Line_1_End_Range: accessed-variable=RpFromSwcSafeFD02Tx.Line_1_End_Range
            REC_RpFromSwcSafeFD02Tx_Line_1_Heading: accessed-variable=RpFromSwcSafeFD02Tx.Line_1_Heading
            REC_RpFromSwcSafeFD02Tx_Line_1_Offset: accessed-variable=RpFromSwcSafeFD02Tx.Line_1_Offset
            REC_RpFromSwcSafeFD02Tx_Line_1_Start_Range: accessed-variable=RpFromSwcSafeFD02Tx.Line_1_Start_Range
            REC_RpFromSwcSafeFD02Tx_Line_1_Type: accessed-variable=RpFromSwcSafeFD02Tx.Line_1_Type
            REC_RpFromSwcSafeFD02Tx_Line_2_Confidence: accessed-variable=RpFromSwcSafeFD02Tx.Line_2_Confidence
            REC_RpFromSwcSafeFD02Tx_Line_2_Curvature: accessed-variable=RpFromSwcSafeFD02Tx.Line_2_Curvature
            REC_RpFromSwcSafeFD02Tx_Line_2_Curvature_Rate: accessed-variable=RpFromSwcSafeFD02Tx.Line_2_Curvature_Rate
            REC_RpFromSwcSafeFD02Tx_Line_2_End_Range: accessed-variable=RpFromSwcSafeFD02Tx.Line_2_End_Range
            REC_RpFromSwcSafeFD02Tx_Line_2_Heading: accessed-variable=RpFromSwcSafeFD02Tx.Line_2_Heading
            REC_RpFromSwcSafeFD02Tx_Line_2_Offset: accessed-variable=RpFromSwcSafeFD02Tx.Line_2_Offset
            REC_RpFromSwcSafeFD02Tx_Line_2_Start_Range: accessed-variable=RpFromSwcSafeFD02Tx.Line_2_Start_Range
            REC_RpFromSwcSafeFD02Tx_Line_2_Type: accessed-variable=RpFromSwcSafeFD02Tx.Line_2_Type
            REC_RpFromSwcSafeFD02Tx_Line_3_Confidence: accessed-variable=RpFromSwcSafeFD02Tx.Line_3_Confidence
            REC_RpFromSwcSafeFD02Tx_Line_3_Curvature: accessed-variable=RpFromSwcSafeFD02Tx.Line_3_Curvature
            REC_RpFromSwcSafeFD02Tx_Line_3_Curvature_Rate: accessed-variable=RpFromSwcSafeFD02Tx.Line_3_Curvature_Rate
            REC_RpFromSwcSafeFD02Tx_Line_3_End_Range: accessed-variable=RpFromSwcSafeFD02Tx.Line_3_End_Range
            REC_RpFromSwcSafeFD02Tx_Line_3_Heading: accessed-variable=RpFromSwcSafeFD02Tx.Line_3_Heading
            REC_RpFromSwcSafeFD02Tx_Line_3_Offset: accessed-variable=RpFromSwcSafeFD02Tx.Line_3_Offset
            REC_RpFromSwcSafeFD02Tx_Line_3_Start_Range: accessed-variable=RpFromSwcSafeFD02Tx.Line_3_Start_Range
            REC_RpFromSwcSafeFD02Tx_Line_3_Type: accessed-variable=RpFromSwcSafeFD02Tx.Line_3_Type
            REC_RpFromSwcSafeFD02Tx_Line_4_Confidence: accessed-variable=RpFromSwcSafeFD02Tx.Line_4_Confidence
            REC_RpFromSwcSafeFD02Tx_Line_4_Curvature: accessed-variable=RpFromSwcSafeFD02Tx.Line_4_Curvature
            REC_RpFromSwcSafeFD02Tx_Line_4_Curvature_Rate: accessed-variable=RpFromSwcSafeFD02Tx.Line_4_Curvature_Rate
            REC_RpFromSwcSafeFD02Tx_Line_4_End_Range: accessed-variable=RpFromSwcSafeFD02Tx.Line_4_End_Range
            REC_RpFromSwcSafeFD02Tx_Line_4_Heading: accessed-variable=RpFromSwcSafeFD02Tx.Line_4_Heading
            REC_RpFromSwcSafeFD02Tx_Line_4_Offset: accessed-variable=RpFromSwcSafeFD02Tx.Line_4_Offset
            REC_RpFromSwcSafeFD02Tx_Line_4_Start_Range: accessed-variable=RpFromSwcSafeFD02Tx.Line_4_Start_Range
            REC_RpFromSwcSafeFD02Tx_Line_4_Type: accessed-variable=RpFromSwcSafeFD02Tx.Line_4_Type
            REC_RpFromSwcSafeFD02Tx_MAC_ADAS_FD_LANES_1: accessed-variable=RpFromSwcSafeFD02Tx.MAC_ADAS_FD_LANES_1
            REC_RpFromSwcSafeFD02Tx_MAC_ADAS_FD_LANES_2: accessed-variable=RpFromSwcSafeFD02Tx.MAC_ADAS_FD_LANES_2
            REC_RpFromSwcSafeFD02Tx_Reserved_for_functional_safety: accessed-variable=RpFromSwcSafeFD02Tx.Reserved_for_functional_safety
            REC_RpFromSwcSafeFD02Tx_Segment_1_Confidence: accessed-variable=RpFromSwcSafeFD02Tx.Segment_1_Confidence
            REC_RpFromSwcSafeFD02Tx_Segment_1_ID: accessed-variable=RpFromSwcSafeFD02Tx.Segment_1_ID
            REC_RpFromSwcSafeFD02Tx_Segment_1_X1: accessed-variable=RpFromSwcSafeFD02Tx.Segment_1_X1
            REC_RpFromSwcSafeFD02Tx_Segment_1_X2: accessed-variable=RpFromSwcSafeFD02Tx.Segment_1_X2
            REC_RpFromSwcSafeFD02Tx_Segment_1_Y1: accessed-variable=RpFromSwcSafeFD02Tx.Segment_1_Y1
            REC_RpFromSwcSafeFD02Tx_Segment_1_Y2: accessed-variable=RpFromSwcSafeFD02Tx.Segment_1_Y2
            REC_RpFromSwcSafeFD02Tx_Segment_2_Confidence: accessed-variable=RpFromSwcSafeFD02Tx.Segment_2_Confidence
            REC_RpFromSwcSafeFD02Tx_Segment_2_ID: accessed-variable=RpFromSwcSafeFD02Tx.Segment_2_ID
            REC_RpFromSwcSafeFD02Tx_Segment_2_X1: accessed-variable=RpFromSwcSafeFD02Tx.Segment_2_X1
            REC_RpFromSwcSafeFD02Tx_Segment_2_X2: accessed-variable=RpFromSwcSafeFD02Tx.Segment_2_X2
            REC_RpFromSwcSafeFD02Tx_Segment_2_Y1: accessed-variable=RpFromSwcSafeFD02Tx.Segment_2_Y1
            REC_RpFromSwcSafeFD02Tx_Segment_2_Y2: accessed-variable=RpFromSwcSafeFD02Tx.Segment_2_Y2
            REC_RpFromSwcSafeFD02Tx_Segment_3_Confidence: accessed-variable=RpFromSwcSafeFD02Tx.Segment_3_Confidence
            REC_RpFromSwcSafeFD02Tx_Segment_3_ID: accessed-variable=RpFromSwcSafeFD02Tx.Segment_3_ID
            REC_RpFromSwcSafeFD02Tx_Segment_3_X1: accessed-variable=RpFromSwcSafeFD02Tx.Segment_3_X1
            REC_RpFromSwcSafeFD02Tx_Segment_3_X2: accessed-variable=RpFromSwcSafeFD02Tx.Segment_3_X2
            REC_RpFromSwcSafeFD02Tx_Segment_3_Y1: accessed-variable=RpFromSwcSafeFD02Tx.Segment_3_Y1
            REC_RpFromSwcSafeFD02Tx_Segment_3_Y2: accessed-variable=RpFromSwcSafeFD02Tx.Segment_3_Y2
            REC_RpFromSwcSafeFD02Tx_Segment_4_Confidence: accessed-variable=RpFromSwcSafeFD02Tx.Segment_4_Confidence
            REC_RpFromSwcSafeFD02Tx_Segment_4_ID: accessed-variable=RpFromSwcSafeFD02Tx.Segment_4_ID
            REC_RpFromSwcSafeFD02Tx_Segment_4_X1: accessed-variable=RpFromSwcSafeFD02Tx.Segment_4_X1
            REC_RpFromSwcSafeFD02Tx_Segment_4_X2: accessed-variable=RpFromSwcSafeFD02Tx.Segment_4_X2
            REC_RpFromSwcSafeFD02Tx_Segment_4_Y1: accessed-variable=RpFromSwcSafeFD02Tx.Segment_4_Y1
            REC_RpFromSwcSafeFD02Tx_Segment_4_Y2: accessed-variable=RpFromSwcSafeFD02Tx.Segment_4_Y2
            REC_RpFromSwcSafeFD02Tx_Segment_5_Confidence: accessed-variable=RpFromSwcSafeFD02Tx.Segment_5_Confidence
            REC_RpFromSwcSafeFD02Tx_Segment_5_ID: accessed-variable=RpFromSwcSafeFD02Tx.Segment_5_ID
            REC_RpFromSwcSafeFD02Tx_Segment_5_X1: accessed-variable=RpFromSwcSafeFD02Tx.Segment_5_X1
            REC_RpFromSwcSafeFD02Tx_Segment_5_X2: accessed-variable=RpFromSwcSafeFD02Tx.Segment_5_X2
            REC_RpFromSwcSafeFD02Tx_Segment_5_Y1: accessed-variable=RpFromSwcSafeFD02Tx.Segment_5_Y1
            REC_RpFromSwcSafeFD02Tx_Segment_5_Y2: accessed-variable=RpFromSwcSafeFD02Tx.Segment_5_Y2
            REC_RpFromSwcSafeFD02Tx_Segment_6_Confidence: accessed-variable=RpFromSwcSafeFD02Tx.Segment_6_Confidence
            REC_RpFromSwcSafeFD02Tx_Segment_6_ID: accessed-variable=RpFromSwcSafeFD02Tx.Segment_6_ID
            REC_RpFromSwcSafeFD02Tx_Segment_6_X1: accessed-variable=RpFromSwcSafeFD02Tx.Segment_6_X1
            REC_RpFromSwcSafeFD02Tx_Segment_6_X2: accessed-variable=RpFromSwcSafeFD02Tx.Segment_6_X2
            REC_RpFromSwcSafeFD02Tx_Segment_6_Y1: accessed-variable=RpFromSwcSafeFD02Tx.Segment_6_Y1
            REC_RpFromSwcSafeFD02Tx_Segment_6_Y2: accessed-variable=RpFromSwcSafeFD02Tx.Segment_6_Y2
            REC_RpFromSwcSafeFD02Tx_Segment_7_Confidence: accessed-variable=RpFromSwcSafeFD02Tx.Segment_7_Confidence
            REC_RpFromSwcSafeFD02Tx_Segment_7_ID: accessed-variable=RpFromSwcSafeFD02Tx.Segment_7_ID
            REC_RpFromSwcSafeFD02Tx_Segment_7_X1: accessed-variable=RpFromSwcSafeFD02Tx.Segment_7_X1
            REC_RpFromSwcSafeFD02Tx_Segment_7_X2: accessed-variable=RpFromSwcSafeFD02Tx.Segment_7_X2
            REC_RpFromSwcSafeFD02Tx_Segment_7_Y1: accessed-variable=RpFromSwcSafeFD02Tx.Segment_7_Y1
            REC_RpFromSwcSafeFD02Tx_Segment_7_Y2: accessed-variable=RpFromSwcSafeFD02Tx.Segment_7_Y2
            REC_RpFromSwcSafeFD02Tx_Segment_8_Confidence: accessed-variable=RpFromSwcSafeFD02Tx.Segment_8_Confidence
            REC_RpFromSwcSafeFD02Tx_Segment_8_ID: accessed-variable=RpFromSwcSafeFD02Tx.Segment_8_ID
            REC_RpFromSwcSafeFD02Tx_Segment_8_X1: accessed-variable=RpFromSwcSafeFD02Tx.Segment_8_X1
            REC_RpFromSwcSafeFD02Tx_Segment_8_X2: accessed-variable=RpFromSwcSafeFD02Tx.Segment_8_X2
            REC_RpFromSwcSafeFD02Tx_Segment_8_Y1: accessed-variable=RpFromSwcSafeFD02Tx.Segment_8_Y1
            REC_RpFromSwcSafeFD02Tx_Segment_8_Y2: accessed-variable=RpFromSwcSafeFD02Tx.Segment_8_Y2
            REC_RpErrFltMcu2_0_Error_Fault_MCU2_0_t: accessed-variable=RpErrFltMcu2_0.Error_Fault_MCU2_0_t
            REC_RpErrFltMcu2_1_Error_Fault_MCU2_1_t: accessed-variable=RpErrFltMcu2_1.Error_Fault_MCU2_1_t
            REC_RpErrFltMpu1_0_Error_Fault_MPU1_0_t: accessed-variable=RpErrFltMpu1_0.Error_Fault_MPU1_0_t
            REC_R_SystemState_SystemState: accessed-variable=R_SystemState.SystemState
            REC_RpKeepAliveResponse_KeepAliveResponse_t: accessed-variable=RpKeepAliveResponse.KeepAliveResponse_t
            REC_RpWdgCheckpointStatusMcu2_0_WdgCheckpointStatus_t: accessed-variable=RpWdgCheckpointStatusMcu2_0.WdgCheckpointStatus_t
            REC_RpWdgCheckpointStatusMcu2_1_WdgCheckpointStatus_t: accessed-variable=RpWdgCheckpointStatusMcu2_1.WdgCheckpointStatus_t
            REC_RpWdgCheckpointStatusMpu1_0_WdgCheckpointStatus_t: accessed-variable=RpWdgCheckpointStatusMpu1_0.WdgCheckpointStatus_t
        data-send-points:
          551 x access:
            SEND_PpToComSafeFD02Tx_AUXCamsRQSts: accessed-variable=PpToComSafeFD02Tx.AUXCamsRQSts
            SEND_PpToComSafeFD02Tx_Alert_CHF: accessed-variable=PpToComSafeFD02Tx.Alert_CHF
            SEND_PpToComSafeFD02Tx_Alert_CHR: accessed-variable=PpToComSafeFD02Tx.Alert_CHR
            SEND_PpToComSafeFD02Tx_Alert_LHF: accessed-variable=PpToComSafeFD02Tx.Alert_LHF
            SEND_PpToComSafeFD02Tx_Alert_LHR: accessed-variable=PpToComSafeFD02Tx.Alert_LHR
            SEND_PpToComSafeFD02Tx_Alert_RHF: accessed-variable=PpToComSafeFD02Tx.Alert_RHF
            SEND_PpToComSafeFD02Tx_Alert_RHR: accessed-variable=PpToComSafeFD02Tx.Alert_RHR
            SEND_PpToComSafeFD02Tx_ChimeActivation_LHF: accessed-variable=PpToComSafeFD02Tx.ChimeActivation_LHF
            SEND_PpToComSafeFD02Tx_ChimeActivation_LHR: accessed-variable=PpToComSafeFD02Tx.ChimeActivation_LHR
            SEND_PpToComSafeFD02Tx_ChimeActivation_RHF: accessed-variable=PpToComSafeFD02Tx.ChimeActivation_RHF
            SEND_PpToComSafeFD02Tx_ChimeActivation_RHR: accessed-variable=PpToComSafeFD02Tx.ChimeActivation_RHR
            SEND_PpToComSafeFD02Tx_DisplayView2: accessed-variable=PpToComSafeFD02Tx.DisplayView2
            SEND_PpToComSafeFD02Tx_FT_PAM_LedControlSts: accessed-variable=PpToComSafeFD02Tx.FT_PAM_LedControlSts
            SEND_PpToComSafeFD02Tx_FrontSensorSts: accessed-variable=PpToComSafeFD02Tx.FrontSensorSts
            SEND_PpToComSafeFD02Tx_Graphic_CHF: accessed-variable=PpToComSafeFD02Tx.Graphic_CHF
            SEND_PpToComSafeFD02Tx_Graphic_CHR: accessed-variable=PpToComSafeFD02Tx.Graphic_CHR
            SEND_PpToComSafeFD02Tx_Graphic_LHF: accessed-variable=PpToComSafeFD02Tx.Graphic_LHF
            SEND_PpToComSafeFD02Tx_Graphic_LHR: accessed-variable=PpToComSafeFD02Tx.Graphic_LHR
            SEND_PpToComSafeFD02Tx_Graphic_RHF: accessed-variable=PpToComSafeFD02Tx.Graphic_RHF
            SEND_PpToComSafeFD02Tx_Graphic_RHR: accessed-variable=PpToComSafeFD02Tx.Graphic_RHR
            SEND_PpToComSafeFD02Tx_HMICode: accessed-variable=PpToComSafeFD02Tx.HMICode
            SEND_PpToComSafeFD02Tx_ImageDefeatRQSts: accessed-variable=PpToComSafeFD02Tx.ImageDefeatRQSts
            SEND_PpToComSafeFD02Tx_MoreCamsRQSts: accessed-variable=PpToComSafeFD02Tx.MoreCamsRQSts
            SEND_PpToComSafeFD02Tx_PAMSystemFault: accessed-variable=PpToComSafeFD02Tx.PAMSystemFault
            SEND_PpToComSafeFD02Tx_PAM_CHIME_REP_RATESts: accessed-variable=PpToComSafeFD02Tx.PAM_CHIME_REP_RATESts
            SEND_PpToComSafeFD02Tx_PAM_CHIME_TYPE: accessed-variable=PpToComSafeFD02Tx.PAM_CHIME_TYPE
            SEND_PpToComSafeFD02Tx_PAM_LedControlSts: accessed-variable=PpToComSafeFD02Tx.PAM_LedControlSts
            SEND_PpToComSafeFD02Tx_PAM_Off_Status: accessed-variable=PpToComSafeFD02Tx.PAM_Off_Status
            SEND_PpToComSafeFD02Tx_PAM_Off_Status_2BT: accessed-variable=PpToComSafeFD02Tx.PAM_Off_Status_2BT
            SEND_PpToComSafeFD02Tx_PAM_PopUpRqst: accessed-variable=PpToComSafeFD02Tx.PAM_PopUpRqst
            SEND_PpToComSafeFD02Tx_PAM_Volume: accessed-variable=PpToComSafeFD02Tx.PAM_Volume
            SEND_PpToComSafeFD02Tx_PPPA_TurnIndicatorRqst: accessed-variable=PpToComSafeFD02Tx.PPPA_TurnIndicatorRqst
            SEND_PpToComSafeFD02Tx_ParkingManeuverActive: accessed-variable=PpToComSafeFD02Tx.ParkingManeuverActive
            SEND_PpToComSafeFD02Tx_RR_PAM_Brk_RqSts: accessed-variable=PpToComSafeFD02Tx.RR_PAM_Brk_RqSts
            SEND_PpToComSafeFD02Tx_RR_PAM_Dist: accessed-variable=PpToComSafeFD02Tx.RR_PAM_Dist
            SEND_PpToComSafeFD02Tx_RR_PAM_StopControlSts: accessed-variable=PpToComSafeFD02Tx.RR_PAM_StopControlSts
            SEND_PpToComSafeFD02Tx_RearSensorSts: accessed-variable=PpToComSafeFD02Tx.RearSensorSts
            SEND_PpToComSafeFD02Tx_SPMControlSts: accessed-variable=PpToComSafeFD02Tx.SPMControlSts
            SEND_PpToComSafeFD02Tx_SPMFailSts: accessed-variable=PpToComSafeFD02Tx.SPMFailSts
            SEND_PpToComSafeFD02Tx_SPMSystemFault: accessed-variable=PpToComSafeFD02Tx.SPMSystemFault
            SEND_PpToComSafeFD02Tx_SPM_LedControlSts: accessed-variable=PpToComSafeFD02Tx.SPM_LedControlSts
            SEND_PpToComSafeFD02Tx_SPM_Screen_Rqst: accessed-variable=PpToComSafeFD02Tx.SPM_Screen_Rqst
            SEND_PpToComSafeFD02Tx_TRSC_LED_Stat: accessed-variable=PpToComSafeFD02Tx.TRSC_LED_Stat
            SEND_PpToSwcSafeFD02Tx_AUXCamsRQSts: accessed-variable=PpToSwcSafeFD02Tx.AUXCamsRQSts
            SEND_PpToSwcSafeFD02Tx_Alert_CHF: accessed-variable=PpToSwcSafeFD02Tx.Alert_CHF
            SEND_PpToSwcSafeFD02Tx_Alert_CHR: accessed-variable=PpToSwcSafeFD02Tx.Alert_CHR
            SEND_PpToSwcSafeFD02Tx_Alert_LHF: accessed-variable=PpToSwcSafeFD02Tx.Alert_LHF
            SEND_PpToSwcSafeFD02Tx_Alert_LHR: accessed-variable=PpToSwcSafeFD02Tx.Alert_LHR
            SEND_PpToSwcSafeFD02Tx_Alert_RHF: accessed-variable=PpToSwcSafeFD02Tx.Alert_RHF
            SEND_PpToSwcSafeFD02Tx_Alert_RHR: accessed-variable=PpToSwcSafeFD02Tx.Alert_RHR
            SEND_PpToSwcSafeFD02Tx_ChimeActivation_LHF: accessed-variable=PpToSwcSafeFD02Tx.ChimeActivation_LHF
            SEND_PpToSwcSafeFD02Tx_ChimeActivation_LHR: accessed-variable=PpToSwcSafeFD02Tx.ChimeActivation_LHR
            SEND_PpToSwcSafeFD02Tx_ChimeActivation_RHF: accessed-variable=PpToSwcSafeFD02Tx.ChimeActivation_RHF
            SEND_PpToSwcSafeFD02Tx_ChimeActivation_RHR: accessed-variable=PpToSwcSafeFD02Tx.ChimeActivation_RHR
            SEND_PpToSwcSafeFD02Tx_DisplayView2: accessed-variable=PpToSwcSafeFD02Tx.DisplayView2
            SEND_PpToSwcSafeFD02Tx_FT_PAM_LedControlSts: accessed-variable=PpToSwcSafeFD02Tx.FT_PAM_LedControlSts
            SEND_PpToSwcSafeFD02Tx_FrontSensorSts: accessed-variable=PpToSwcSafeFD02Tx.FrontSensorSts
            SEND_PpToSwcSafeFD02Tx_Graphic_CHF: accessed-variable=PpToSwcSafeFD02Tx.Graphic_CHF
            SEND_PpToSwcSafeFD02Tx_Graphic_CHR: accessed-variable=PpToSwcSafeFD02Tx.Graphic_CHR
            SEND_PpToSwcSafeFD02Tx_Graphic_LHF: accessed-variable=PpToSwcSafeFD02Tx.Graphic_LHF
            SEND_PpToSwcSafeFD02Tx_Graphic_LHR: accessed-variable=PpToSwcSafeFD02Tx.Graphic_LHR
            SEND_PpToSwcSafeFD02Tx_Graphic_RHF: accessed-variable=PpToSwcSafeFD02Tx.Graphic_RHF
            SEND_PpToSwcSafeFD02Tx_Graphic_RHR: accessed-variable=PpToSwcSafeFD02Tx.Graphic_RHR
            SEND_PpToSwcSafeFD02Tx_HMICode: accessed-variable=PpToSwcSafeFD02Tx.HMICode
            SEND_PpToSwcSafeFD02Tx_ImageDefeatRQSts: accessed-variable=PpToSwcSafeFD02Tx.ImageDefeatRQSts
            SEND_PpToSwcSafeFD02Tx_MoreCamsRQSts: accessed-variable=PpToSwcSafeFD02Tx.MoreCamsRQSts
            SEND_PpToSwcSafeFD02Tx_PAMSystemFault: accessed-variable=PpToSwcSafeFD02Tx.PAMSystemFault
            SEND_PpToSwcSafeFD02Tx_PAM_CHIME_REP_RATESts: accessed-variable=PpToSwcSafeFD02Tx.PAM_CHIME_REP_RATESts
            SEND_PpToSwcSafeFD02Tx_PAM_CHIME_TYPE: accessed-variable=PpToSwcSafeFD02Tx.PAM_CHIME_TYPE
            SEND_PpToSwcSafeFD02Tx_PAM_LedControlSts: accessed-variable=PpToSwcSafeFD02Tx.PAM_LedControlSts
            SEND_PpToSwcSafeFD02Tx_PAM_Off_Status: accessed-variable=PpToSwcSafeFD02Tx.PAM_Off_Status
            SEND_PpToSwcSafeFD02Tx_PAM_Off_Status_2BT: accessed-variable=PpToSwcSafeFD02Tx.PAM_Off_Status_2BT
            SEND_PpToSwcSafeFD02Tx_PAM_PopUpRqst: accessed-variable=PpToSwcSafeFD02Tx.PAM_PopUpRqst
            SEND_PpToSwcSafeFD02Tx_PAM_Volume: accessed-variable=PpToSwcSafeFD02Tx.PAM_Volume
            SEND_PpToSwcSafeFD02Tx_PPPA_TurnIndicatorRqst: accessed-variable=PpToSwcSafeFD02Tx.PPPA_TurnIndicatorRqst
            SEND_PpToSwcSafeFD02Tx_ParkingManeuverActive: accessed-variable=PpToSwcSafeFD02Tx.ParkingManeuverActive
            SEND_PpToSwcSafeFD02Tx_RR_PAM_Brk_RqSts: accessed-variable=PpToSwcSafeFD02Tx.RR_PAM_Brk_RqSts
            SEND_PpToSwcSafeFD02Tx_RR_PAM_Dist: accessed-variable=PpToSwcSafeFD02Tx.RR_PAM_Dist
            SEND_PpToSwcSafeFD02Tx_RR_PAM_StopControlSts: accessed-variable=PpToSwcSafeFD02Tx.RR_PAM_StopControlSts
            SEND_PpToSwcSafeFD02Tx_RearSensorSts: accessed-variable=PpToSwcSafeFD02Tx.RearSensorSts
            SEND_PpToSwcSafeFD02Tx_SPMControlSts: accessed-variable=PpToSwcSafeFD02Tx.SPMControlSts
            SEND_PpToSwcSafeFD02Tx_SPMFailSts: accessed-variable=PpToSwcSafeFD02Tx.SPMFailSts
            SEND_PpToSwcSafeFD02Tx_SPMSystemFault: accessed-variable=PpToSwcSafeFD02Tx.SPMSystemFault
            SEND_PpToSwcSafeFD02Tx_SPM_LedControlSts: accessed-variable=PpToSwcSafeFD02Tx.SPM_LedControlSts
            SEND_PpToSwcSafeFD02Tx_SPM_Screen_Rqst: accessed-variable=PpToSwcSafeFD02Tx.SPM_Screen_Rqst
            SEND_PpToSwcSafeFD02Tx_TRSC_LED_Stat: accessed-variable=PpToSwcSafeFD02Tx.TRSC_LED_Stat
            SEND_PpToComSafeFD14Tx_FD14_ManoeuvrePhase: accessed-variable=PpToComSafeFD14Tx.FD14_ManoeuvrePhase
            SEND_PpToComSafeFD14Tx_FD14_PPPA_AccelMax: accessed-variable=PpToComSafeFD14Tx.FD14_PPPA_AccelMax
            SEND_PpToComSafeFD14Tx_FD14_PPPA_AccelMin: accessed-variable=PpToComSafeFD14Tx.FD14_PPPA_AccelMin
            SEND_PpToComSafeFD14Tx_FD14_PPPA_DecelMax: accessed-variable=PpToComSafeFD14Tx.FD14_PPPA_DecelMax
            SEND_PpToComSafeFD14Tx_FD14_PPPA_DecelMin: accessed-variable=PpToComSafeFD14Tx.FD14_PPPA_DecelMin
            SEND_PpToComSafeFD14Tx_FD14_PPPA_Interface_BSM: accessed-variable=PpToComSafeFD14Tx.FD14_PPPA_Interface_BSM
            SEND_PpToComSafeFD14Tx_FD14_PPPA_JerkAccelMax: accessed-variable=PpToComSafeFD14Tx.FD14_PPPA_JerkAccelMax
            SEND_PpToComSafeFD14Tx_FD14_PPPA_JerkAccelMin: accessed-variable=PpToComSafeFD14Tx.FD14_PPPA_JerkAccelMin
            SEND_PpToComSafeFD14Tx_FD14_PPPA_JerkDecelMax: accessed-variable=PpToComSafeFD14Tx.FD14_PPPA_JerkDecelMax
            SEND_PpToComSafeFD14Tx_FD14_PPPA_JerkDecelMin: accessed-variable=PpToComSafeFD14Tx.FD14_PPPA_JerkDecelMin
            SEND_PpToComSafeFD14Tx_FD14_PPPA_MaxSpeed: accessed-variable=PpToComSafeFD14Tx.FD14_PPPA_MaxSpeed
            SEND_PpToComSafeFD14Tx_FD14_PPPA_StandstillRqst: accessed-variable=PpToComSafeFD14Tx.FD14_PPPA_StandstillRqst
            SEND_PpToComSafeFD14Tx_FD14_PPPA_TargetDistance: accessed-variable=PpToComSafeFD14Tx.FD14_PPPA_TargetDistance
            SEND_PpToComSafeFD14Tx_FD14_ParkingGearShiftReq: accessed-variable=PpToComSafeFD14Tx.FD14_ParkingGearShiftReq
            SEND_PpToComSafeFD14Tx_FD14_RR_PAM_Brk_RqSts: accessed-variable=PpToComSafeFD14Tx.FD14_RR_PAM_Brk_RqSts
            SEND_PpToComSafeFD14Tx_FD14_RR_PAM_Dist: accessed-variable=PpToComSafeFD14Tx.FD14_RR_PAM_Dist
            SEND_PpToComSafeFD14Tx_FD14_SPM_Lat_Ctrl_RequestSts: accessed-variable=PpToComSafeFD14Tx.FD14_SPM_Lat_Ctrl_RequestSts
            SEND_PpToComSafeFD14Tx_FD14_TorqueOverlaySteeringReq_SPM: accessed-variable=PpToComSafeFD14Tx.FD14_TorqueOverlaySteeringReq_SPM
            SEND_PpToSwcSafeFD14Tx_FD14_ManoeuvrePhase: accessed-variable=PpToSwcSafeFD14Tx.FD14_ManoeuvrePhase
            SEND_PpToSwcSafeFD14Tx_FD14_PPPA_AccelMax: accessed-variable=PpToSwcSafeFD14Tx.FD14_PPPA_AccelMax
            SEND_PpToSwcSafeFD14Tx_FD14_PPPA_AccelMin: accessed-variable=PpToSwcSafeFD14Tx.FD14_PPPA_AccelMin
            SEND_PpToSwcSafeFD14Tx_FD14_PPPA_DecelMax: accessed-variable=PpToSwcSafeFD14Tx.FD14_PPPA_DecelMax
            SEND_PpToSwcSafeFD14Tx_FD14_PPPA_DecelMin: accessed-variable=PpToSwcSafeFD14Tx.FD14_PPPA_DecelMin
            SEND_PpToSwcSafeFD14Tx_FD14_PPPA_Interface_BSM: accessed-variable=PpToSwcSafeFD14Tx.FD14_PPPA_Interface_BSM
            SEND_PpToSwcSafeFD14Tx_FD14_PPPA_JerkAccelMax: accessed-variable=PpToSwcSafeFD14Tx.FD14_PPPA_JerkAccelMax
            SEND_PpToSwcSafeFD14Tx_FD14_PPPA_JerkAccelMin: accessed-variable=PpToSwcSafeFD14Tx.FD14_PPPA_JerkAccelMin
            SEND_PpToSwcSafeFD14Tx_FD14_PPPA_JerkDecelMax: accessed-variable=PpToSwcSafeFD14Tx.FD14_PPPA_JerkDecelMax
            SEND_PpToSwcSafeFD14Tx_FD14_PPPA_JerkDecelMin: accessed-variable=PpToSwcSafeFD14Tx.FD14_PPPA_JerkDecelMin
            SEND_PpToSwcSafeFD14Tx_FD14_PPPA_MaxSpeed: accessed-variable=PpToSwcSafeFD14Tx.FD14_PPPA_MaxSpeed
            SEND_PpToSwcSafeFD14Tx_FD14_PPPA_StandstillRqst: accessed-variable=PpToSwcSafeFD14Tx.FD14_PPPA_StandstillRqst
            SEND_PpToSwcSafeFD14Tx_FD14_PPPA_TargetDistance: accessed-variable=PpToSwcSafeFD14Tx.FD14_PPPA_TargetDistance
            SEND_PpToSwcSafeFD14Tx_FD14_ParkingGearShiftReq: accessed-variable=PpToSwcSafeFD14Tx.FD14_ParkingGearShiftReq
            SEND_PpToSwcSafeFD14Tx_FD14_RR_PAM_Brk_RqSts: accessed-variable=PpToSwcSafeFD14Tx.FD14_RR_PAM_Brk_RqSts
            SEND_PpToSwcSafeFD14Tx_FD14_RR_PAM_Dist: accessed-variable=PpToSwcSafeFD14Tx.FD14_RR_PAM_Dist
            SEND_PpToSwcSafeFD14Tx_FD14_SPM_Lat_Ctrl_RequestSts: accessed-variable=PpToSwcSafeFD14Tx.FD14_SPM_Lat_Ctrl_RequestSts
            SEND_PpToSwcSafeFD14Tx_FD14_TorqueOverlaySteeringReq_SPM: accessed-variable=PpToSwcSafeFD14Tx.FD14_TorqueOverlaySteeringReq_SPM
            SEND_PpToComSafeFD14Tx_FD14_Camera_Status: accessed-variable=PpToComSafeFD14Tx.FD14_Camera_Status
            SEND_PpToComSafeFD14Tx_FD14_Cntr_ADAS_FD_LANES_1: accessed-variable=PpToComSafeFD14Tx.FD14_Cntr_ADAS_FD_LANES_1
            SEND_PpToComSafeFD14Tx_FD14_Cntr_ADAS_FD_LANES_2: accessed-variable=PpToComSafeFD14Tx.FD14_Cntr_ADAS_FD_LANES_2
            SEND_PpToComSafeFD14Tx_FD14_FOD_Confidence: accessed-variable=PpToComSafeFD14Tx.FD14_FOD_Confidence
            SEND_PpToComSafeFD14Tx_FD14_Frame_Index_Lanes_1: accessed-variable=PpToComSafeFD14Tx.FD14_Frame_Index_Lanes_1
            SEND_PpToComSafeFD14Tx_FD14_Frame_Index_Lanes_2: accessed-variable=PpToComSafeFD14Tx.FD14_Frame_Index_Lanes_2
            SEND_PpToComSafeFD14Tx_FD14_Health_Front_Object_Detection: accessed-variable=PpToComSafeFD14Tx.FD14_Health_Front_Object_Detection
            SEND_PpToComSafeFD14Tx_FD14_Health_Lane_Detection: accessed-variable=PpToComSafeFD14Tx.FD14_Health_Lane_Detection
            SEND_PpToComSafeFD14Tx_FD14_Line_1_Confidence: accessed-variable=PpToComSafeFD14Tx.FD14_Line_1_Confidence
            SEND_PpToComSafeFD14Tx_FD14_Line_1_Curvature: accessed-variable=PpToComSafeFD14Tx.FD14_Line_1_Curvature
            SEND_PpToComSafeFD14Tx_FD14_Line_1_Curvature_Rate: accessed-variable=PpToComSafeFD14Tx.FD14_Line_1_Curvature_Rate
            SEND_PpToComSafeFD14Tx_FD14_Line_1_End_Range: accessed-variable=PpToComSafeFD14Tx.FD14_Line_1_End_Range
            SEND_PpToComSafeFD14Tx_FD14_Line_1_Heading: accessed-variable=PpToComSafeFD14Tx.FD14_Line_1_Heading
            SEND_PpToComSafeFD14Tx_FD14_Line_1_Offset: accessed-variable=PpToComSafeFD14Tx.FD14_Line_1_Offset
            SEND_PpToComSafeFD14Tx_FD14_Line_1_Start_Range: accessed-variable=PpToComSafeFD14Tx.FD14_Line_1_Start_Range
            SEND_PpToComSafeFD14Tx_FD14_Line_1_Type: accessed-variable=PpToComSafeFD14Tx.FD14_Line_1_Type
            SEND_PpToComSafeFD14Tx_FD14_Line_2_Confidence: accessed-variable=PpToComSafeFD14Tx.FD14_Line_2_Confidence
            SEND_PpToComSafeFD14Tx_FD14_Line_2_Curvature: accessed-variable=PpToComSafeFD14Tx.FD14_Line_2_Curvature
            SEND_PpToComSafeFD14Tx_FD14_Line_2_Curvature_Rate: accessed-variable=PpToComSafeFD14Tx.FD14_Line_2_Curvature_Rate
            SEND_PpToComSafeFD14Tx_FD14_Line_2_End_Range: accessed-variable=PpToComSafeFD14Tx.FD14_Line_2_End_Range
            SEND_PpToComSafeFD14Tx_FD14_Line_2_Heading: accessed-variable=PpToComSafeFD14Tx.FD14_Line_2_Heading
            SEND_PpToComSafeFD14Tx_FD14_Line_2_Offset: accessed-variable=PpToComSafeFD14Tx.FD14_Line_2_Offset
            SEND_PpToComSafeFD14Tx_FD14_Line_2_Start_Range: accessed-variable=PpToComSafeFD14Tx.FD14_Line_2_Start_Range
            SEND_PpToComSafeFD14Tx_FD14_Line_2_Type: accessed-variable=PpToComSafeFD14Tx.FD14_Line_2_Type
            SEND_PpToComSafeFD14Tx_FD14_Line_3_Confidence: accessed-variable=PpToComSafeFD14Tx.FD14_Line_3_Confidence
            SEND_PpToComSafeFD14Tx_FD14_Line_3_Curvature: accessed-variable=PpToComSafeFD14Tx.FD14_Line_3_Curvature
            SEND_PpToComSafeFD14Tx_FD14_Line_3_Curvature_Rate: accessed-variable=PpToComSafeFD14Tx.FD14_Line_3_Curvature_Rate
            SEND_PpToComSafeFD14Tx_FD14_Line_3_End_Range: accessed-variable=PpToComSafeFD14Tx.FD14_Line_3_End_Range
            SEND_PpToComSafeFD14Tx_FD14_Line_3_Heading: accessed-variable=PpToComSafeFD14Tx.FD14_Line_3_Heading
            SEND_PpToComSafeFD14Tx_FD14_Line_3_Offset: accessed-variable=PpToComSafeFD14Tx.FD14_Line_3_Offset
            SEND_PpToComSafeFD14Tx_FD14_Line_3_Start_Range: accessed-variable=PpToComSafeFD14Tx.FD14_Line_3_Start_Range
            SEND_PpToComSafeFD14Tx_FD14_Line_3_Type: accessed-variable=PpToComSafeFD14Tx.FD14_Line_3_Type
            SEND_PpToComSafeFD14Tx_FD14_Line_4_Confidence: accessed-variable=PpToComSafeFD14Tx.FD14_Line_4_Confidence
            SEND_PpToComSafeFD14Tx_FD14_Line_4_Curvature: accessed-variable=PpToComSafeFD14Tx.FD14_Line_4_Curvature
            SEND_PpToComSafeFD14Tx_FD14_Line_4_Curvature_Rate: accessed-variable=PpToComSafeFD14Tx.FD14_Line_4_Curvature_Rate
            SEND_PpToComSafeFD14Tx_FD14_Line_4_End_Range: accessed-variable=PpToComSafeFD14Tx.FD14_Line_4_End_Range
            SEND_PpToComSafeFD14Tx_FD14_Line_4_Heading: accessed-variable=PpToComSafeFD14Tx.FD14_Line_4_Heading
            SEND_PpToComSafeFD14Tx_FD14_Line_4_Offset: accessed-variable=PpToComSafeFD14Tx.FD14_Line_4_Offset
            SEND_PpToComSafeFD14Tx_FD14_Line_4_Start_Range: accessed-variable=PpToComSafeFD14Tx.FD14_Line_4_Start_Range
            SEND_PpToComSafeFD14Tx_FD14_Line_4_Type: accessed-variable=PpToComSafeFD14Tx.FD14_Line_4_Type
            SEND_PpToComSafeFD14Tx_FD14_MAC_ADAS_FD_LANES_1: accessed-variable=PpToComSafeFD14Tx.FD14_MAC_ADAS_FD_LANES_1
            SEND_PpToComSafeFD14Tx_FD14_MAC_ADAS_FD_LANES_2: accessed-variable=PpToComSafeFD14Tx.FD14_MAC_ADAS_FD_LANES_2
            SEND_PpToComSafeFD14Tx_FD14_ParkingManeuverActive: accessed-variable=PpToComSafeFD14Tx.FD14_ParkingManeuverActive
            SEND_PpToComSafeFD14Tx_FD14_Reserved_for_functional_safety: accessed-variable=PpToComSafeFD14Tx.FD14_Reserved_for_functional_safety
            SEND_PpToComSafeFD14Tx_FD14_Segment_1_Confidence: accessed-variable=PpToComSafeFD14Tx.FD14_Segment_1_Confidence
            SEND_PpToComSafeFD14Tx_FD14_Segment_1_ID: accessed-variable=PpToComSafeFD14Tx.FD14_Segment_1_ID
            SEND_PpToComSafeFD14Tx_FD14_Segment_1_X1: accessed-variable=PpToComSafeFD14Tx.FD14_Segment_1_X1
            SEND_PpToComSafeFD14Tx_FD14_Segment_1_X2: accessed-variable=PpToComSafeFD14Tx.FD14_Segment_1_X2
            SEND_PpToComSafeFD14Tx_FD14_Segment_1_Y1: accessed-variable=PpToComSafeFD14Tx.FD14_Segment_1_Y1
            SEND_PpToComSafeFD14Tx_FD14_Segment_1_Y2: accessed-variable=PpToComSafeFD14Tx.FD14_Segment_1_Y2
            SEND_PpToComSafeFD14Tx_FD14_Segment_2_Confidence: accessed-variable=PpToComSafeFD14Tx.FD14_Segment_2_Confidence
            SEND_PpToComSafeFD14Tx_FD14_Segment_2_ID: accessed-variable=PpToComSafeFD14Tx.FD14_Segment_2_ID
            SEND_PpToComSafeFD14Tx_FD14_Segment_2_X1: accessed-variable=PpToComSafeFD14Tx.FD14_Segment_2_X1
            SEND_PpToComSafeFD14Tx_FD14_Segment_2_X2: accessed-variable=PpToComSafeFD14Tx.FD14_Segment_2_X2
            SEND_PpToComSafeFD14Tx_FD14_Segment_2_Y1: accessed-variable=PpToComSafeFD14Tx.FD14_Segment_2_Y1
            SEND_PpToComSafeFD14Tx_FD14_Segment_2_Y2: accessed-variable=PpToComSafeFD14Tx.FD14_Segment_2_Y2
            SEND_PpToComSafeFD14Tx_FD14_Segment_3_Confidence: accessed-variable=PpToComSafeFD14Tx.FD14_Segment_3_Confidence
            SEND_PpToComSafeFD14Tx_FD14_Segment_3_ID: accessed-variable=PpToComSafeFD14Tx.FD14_Segment_3_ID
            SEND_PpToComSafeFD14Tx_FD14_Segment_3_X1: accessed-variable=PpToComSafeFD14Tx.FD14_Segment_3_X1
            SEND_PpToComSafeFD14Tx_FD14_Segment_3_X2: accessed-variable=PpToComSafeFD14Tx.FD14_Segment_3_X2
            SEND_PpToComSafeFD14Tx_FD14_Segment_3_Y1: accessed-variable=PpToComSafeFD14Tx.FD14_Segment_3_Y1
            SEND_PpToComSafeFD14Tx_FD14_Segment_3_Y2: accessed-variable=PpToComSafeFD14Tx.FD14_Segment_3_Y2
            SEND_PpToComSafeFD14Tx_FD14_Segment_4_Confidence: accessed-variable=PpToComSafeFD14Tx.FD14_Segment_4_Confidence
            SEND_PpToComSafeFD14Tx_FD14_Segment_4_ID: accessed-variable=PpToComSafeFD14Tx.FD14_Segment_4_ID
            SEND_PpToComSafeFD14Tx_FD14_Segment_4_X1: accessed-variable=PpToComSafeFD14Tx.FD14_Segment_4_X1
            SEND_PpToComSafeFD14Tx_FD14_Segment_4_X2: accessed-variable=PpToComSafeFD14Tx.FD14_Segment_4_X2
            SEND_PpToComSafeFD14Tx_FD14_Segment_4_Y1: accessed-variable=PpToComSafeFD14Tx.FD14_Segment_4_Y1
            SEND_PpToComSafeFD14Tx_FD14_Segment_4_Y2: accessed-variable=PpToComSafeFD14Tx.FD14_Segment_4_Y2
            SEND_PpToComSafeFD14Tx_FD14_Segment_5_Confidence: accessed-variable=PpToComSafeFD14Tx.FD14_Segment_5_Confidence
            SEND_PpToComSafeFD14Tx_FD14_Segment_5_ID: accessed-variable=PpToComSafeFD14Tx.FD14_Segment_5_ID
            SEND_PpToComSafeFD14Tx_FD14_Segment_5_X1: accessed-variable=PpToComSafeFD14Tx.FD14_Segment_5_X1
            SEND_PpToComSafeFD14Tx_FD14_Segment_5_X2: accessed-variable=PpToComSafeFD14Tx.FD14_Segment_5_X2
            SEND_PpToComSafeFD14Tx_FD14_Segment_5_Y1: accessed-variable=PpToComSafeFD14Tx.FD14_Segment_5_Y1
            SEND_PpToComSafeFD14Tx_FD14_Segment_5_Y2: accessed-variable=PpToComSafeFD14Tx.FD14_Segment_5_Y2
            SEND_PpToComSafeFD14Tx_FD14_Segment_6_Confidence: accessed-variable=PpToComSafeFD14Tx.FD14_Segment_6_Confidence
            SEND_PpToComSafeFD14Tx_FD14_Segment_6_ID: accessed-variable=PpToComSafeFD14Tx.FD14_Segment_6_ID
            SEND_PpToComSafeFD14Tx_FD14_Segment_6_X1: accessed-variable=PpToComSafeFD14Tx.FD14_Segment_6_X1
            SEND_PpToComSafeFD14Tx_FD14_Segment_6_X2: accessed-variable=PpToComSafeFD14Tx.FD14_Segment_6_X2
            SEND_PpToComSafeFD14Tx_FD14_Segment_6_Y1: accessed-variable=PpToComSafeFD14Tx.FD14_Segment_6_Y1
            SEND_PpToComSafeFD14Tx_FD14_Segment_6_Y2: accessed-variable=PpToComSafeFD14Tx.FD14_Segment_6_Y2
            SEND_PpToComSafeFD14Tx_FD14_Segment_7_Confidence: accessed-variable=PpToComSafeFD14Tx.FD14_Segment_7_Confidence
            SEND_PpToComSafeFD14Tx_FD14_Segment_7_ID: accessed-variable=PpToComSafeFD14Tx.FD14_Segment_7_ID
            SEND_PpToComSafeFD14Tx_FD14_Segment_7_X1: accessed-variable=PpToComSafeFD14Tx.FD14_Segment_7_X1
            SEND_PpToComSafeFD14Tx_FD14_Segment_7_X2: accessed-variable=PpToComSafeFD14Tx.FD14_Segment_7_X2
            SEND_PpToComSafeFD14Tx_FD14_Segment_7_Y1: accessed-variable=PpToComSafeFD14Tx.FD14_Segment_7_Y1
            SEND_PpToComSafeFD14Tx_FD14_Segment_7_Y2: accessed-variable=PpToComSafeFD14Tx.FD14_Segment_7_Y2
            SEND_PpToComSafeFD14Tx_FD14_Segment_8_Confidence: accessed-variable=PpToComSafeFD14Tx.FD14_Segment_8_Confidence
            SEND_PpToComSafeFD14Tx_FD14_Segment_8_ID: accessed-variable=PpToComSafeFD14Tx.FD14_Segment_8_ID
            SEND_PpToComSafeFD14Tx_FD14_Segment_8_X1: accessed-variable=PpToComSafeFD14Tx.FD14_Segment_8_X1
            SEND_PpToComSafeFD14Tx_FD14_Segment_8_X2: accessed-variable=PpToComSafeFD14Tx.FD14_Segment_8_X2
            SEND_PpToComSafeFD14Tx_FD14_Segment_8_Y1: accessed-variable=PpToComSafeFD14Tx.FD14_Segment_8_Y1
            SEND_PpToComSafeFD14Tx_FD14_Segment_8_Y2: accessed-variable=PpToComSafeFD14Tx.FD14_Segment_8_Y2
            SEND_PpToSwcSafeFD14Tx_FD14_Camera_Status: accessed-variable=PpToSwcSafeFD14Tx.FD14_Camera_Status
            SEND_PpToSwcSafeFD14Tx_FD14_Cntr_ADAS_FD_LANES_1: accessed-variable=PpToSwcSafeFD14Tx.FD14_Cntr_ADAS_FD_LANES_1
            SEND_PpToSwcSafeFD14Tx_FD14_Cntr_ADAS_FD_LANES_2: accessed-variable=PpToSwcSafeFD14Tx.FD14_Cntr_ADAS_FD_LANES_2
            SEND_PpToSwcSafeFD14Tx_FD14_FOD_Confidence: accessed-variable=PpToSwcSafeFD14Tx.FD14_FOD_Confidence
            SEND_PpToSwcSafeFD14Tx_FD14_Frame_Index_Lanes_1: accessed-variable=PpToSwcSafeFD14Tx.FD14_Frame_Index_Lanes_1
            SEND_PpToSwcSafeFD14Tx_FD14_Frame_Index_Lanes_2: accessed-variable=PpToSwcSafeFD14Tx.FD14_Frame_Index_Lanes_2
            SEND_PpToSwcSafeFD14Tx_FD14_Health_Front_Object_Detection: accessed-variable=PpToSwcSafeFD14Tx.FD14_Health_Front_Object_Detection
            SEND_PpToSwcSafeFD14Tx_FD14_Health_Lane_Detection: accessed-variable=PpToSwcSafeFD14Tx.FD14_Health_Lane_Detection
            SEND_PpToSwcSafeFD14Tx_FD14_Line_1_Confidence: accessed-variable=PpToSwcSafeFD14Tx.FD14_Line_1_Confidence
            SEND_PpToSwcSafeFD14Tx_FD14_Line_1_Curvature: accessed-variable=PpToSwcSafeFD14Tx.FD14_Line_1_Curvature
            SEND_PpToSwcSafeFD14Tx_FD14_Line_1_Curvature_Rate: accessed-variable=PpToSwcSafeFD14Tx.FD14_Line_1_Curvature_Rate
            SEND_PpToSwcSafeFD14Tx_FD14_Line_1_End_Range: accessed-variable=PpToSwcSafeFD14Tx.FD14_Line_1_End_Range
            SEND_PpToSwcSafeFD14Tx_FD14_Line_1_Heading: accessed-variable=PpToSwcSafeFD14Tx.FD14_Line_1_Heading
            SEND_PpToSwcSafeFD14Tx_FD14_Line_1_Offset: accessed-variable=PpToSwcSafeFD14Tx.FD14_Line_1_Offset
            SEND_PpToSwcSafeFD14Tx_FD14_Line_1_Start_Range: accessed-variable=PpToSwcSafeFD14Tx.FD14_Line_1_Start_Range
            SEND_PpToSwcSafeFD14Tx_FD14_Line_1_Type: accessed-variable=PpToSwcSafeFD14Tx.FD14_Line_1_Type
            SEND_PpToSwcSafeFD14Tx_FD14_Line_2_Confidence: accessed-variable=PpToSwcSafeFD14Tx.FD14_Line_2_Confidence
            SEND_PpToSwcSafeFD14Tx_FD14_Line_2_Curvature: accessed-variable=PpToSwcSafeFD14Tx.FD14_Line_2_Curvature
            SEND_PpToSwcSafeFD14Tx_FD14_Line_2_Curvature_Rate: accessed-variable=PpToSwcSafeFD14Tx.FD14_Line_2_Curvature_Rate
            SEND_PpToSwcSafeFD14Tx_FD14_Line_2_End_Range: accessed-variable=PpToSwcSafeFD14Tx.FD14_Line_2_End_Range
            SEND_PpToSwcSafeFD14Tx_FD14_Line_2_Heading: accessed-variable=PpToSwcSafeFD14Tx.FD14_Line_2_Heading
            SEND_PpToSwcSafeFD14Tx_FD14_Line_2_Offset: accessed-variable=PpToSwcSafeFD14Tx.FD14_Line_2_Offset
            SEND_PpToSwcSafeFD14Tx_FD14_Line_2_Start_Range: accessed-variable=PpToSwcSafeFD14Tx.FD14_Line_2_Start_Range
            SEND_PpToSwcSafeFD14Tx_FD14_Line_2_Type: accessed-variable=PpToSwcSafeFD14Tx.FD14_Line_2_Type
            SEND_PpToSwcSafeFD14Tx_FD14_Line_3_Confidence: accessed-variable=PpToSwcSafeFD14Tx.FD14_Line_3_Confidence
            SEND_PpToSwcSafeFD14Tx_FD14_Line_3_Curvature: accessed-variable=PpToSwcSafeFD14Tx.FD14_Line_3_Curvature
            SEND_PpToSwcSafeFD14Tx_FD14_Line_3_Curvature_Rate: accessed-variable=PpToSwcSafeFD14Tx.FD14_Line_3_Curvature_Rate
            SEND_PpToSwcSafeFD14Tx_FD14_Line_3_End_Range: accessed-variable=PpToSwcSafeFD14Tx.FD14_Line_3_End_Range
            SEND_PpToSwcSafeFD14Tx_FD14_Line_3_Heading: accessed-variable=PpToSwcSafeFD14Tx.FD14_Line_3_Heading
            SEND_PpToSwcSafeFD14Tx_FD14_Line_3_Offset: accessed-variable=PpToSwcSafeFD14Tx.FD14_Line_3_Offset
            SEND_PpToSwcSafeFD14Tx_FD14_Line_3_Start_Range: accessed-variable=PpToSwcSafeFD14Tx.FD14_Line_3_Start_Range
            SEND_PpToSwcSafeFD14Tx_FD14_Line_3_Type: accessed-variable=PpToSwcSafeFD14Tx.FD14_Line_3_Type
            SEND_PpToSwcSafeFD14Tx_FD14_Line_4_Confidence: accessed-variable=PpToSwcSafeFD14Tx.FD14_Line_4_Confidence
            SEND_PpToSwcSafeFD14Tx_FD14_Line_4_Curvature: accessed-variable=PpToSwcSafeFD14Tx.FD14_Line_4_Curvature
            SEND_PpToSwcSafeFD14Tx_FD14_Line_4_Curvature_Rate: accessed-variable=PpToSwcSafeFD14Tx.FD14_Line_4_Curvature_Rate
            SEND_PpToSwcSafeFD14Tx_FD14_Line_4_End_Range: accessed-variable=PpToSwcSafeFD14Tx.FD14_Line_4_End_Range
            SEND_PpToSwcSafeFD14Tx_FD14_Line_4_Heading: accessed-variable=PpToSwcSafeFD14Tx.FD14_Line_4_Heading
            SEND_PpToSwcSafeFD14Tx_FD14_Line_4_Offset: accessed-variable=PpToSwcSafeFD14Tx.FD14_Line_4_Offset
            SEND_PpToSwcSafeFD14Tx_FD14_Line_4_Start_Range: accessed-variable=PpToSwcSafeFD14Tx.FD14_Line_4_Start_Range
            SEND_PpToSwcSafeFD14Tx_FD14_Line_4_Type: accessed-variable=PpToSwcSafeFD14Tx.FD14_Line_4_Type
            SEND_PpToSwcSafeFD14Tx_FD14_MAC_ADAS_FD_LANES_1: accessed-variable=PpToSwcSafeFD14Tx.FD14_MAC_ADAS_FD_LANES_1
            SEND_PpToSwcSafeFD14Tx_FD14_MAC_ADAS_FD_LANES_2: accessed-variable=PpToSwcSafeFD14Tx.FD14_MAC_ADAS_FD_LANES_2
            SEND_PpToSwcSafeFD14Tx_FD14_ParkingManeuverActive: accessed-variable=PpToSwcSafeFD14Tx.FD14_ParkingManeuverActive
            SEND_PpToSwcSafeFD14Tx_FD14_Reserved_for_functional_safety: accessed-variable=PpToSwcSafeFD14Tx.FD14_Reserved_for_functional_safety
            SEND_PpToSwcSafeFD14Tx_FD14_Segment_1_Confidence: accessed-variable=PpToSwcSafeFD14Tx.FD14_Segment_1_Confidence
            SEND_PpToSwcSafeFD14Tx_FD14_Segment_1_ID: accessed-variable=PpToSwcSafeFD14Tx.FD14_Segment_1_ID
            SEND_PpToSwcSafeFD14Tx_FD14_Segment_1_X1: accessed-variable=PpToSwcSafeFD14Tx.FD14_Segment_1_X1
            SEND_PpToSwcSafeFD14Tx_FD14_Segment_1_X2: accessed-variable=PpToSwcSafeFD14Tx.FD14_Segment_1_X2
            SEND_PpToSwcSafeFD14Tx_FD14_Segment_1_Y1: accessed-variable=PpToSwcSafeFD14Tx.FD14_Segment_1_Y1
            SEND_PpToSwcSafeFD14Tx_FD14_Segment_1_Y2: accessed-variable=PpToSwcSafeFD14Tx.FD14_Segment_1_Y2
            SEND_PpToSwcSafeFD14Tx_FD14_Segment_2_Confidence: accessed-variable=PpToSwcSafeFD14Tx.FD14_Segment_2_Confidence
            SEND_PpToSwcSafeFD14Tx_FD14_Segment_2_ID: accessed-variable=PpToSwcSafeFD14Tx.FD14_Segment_2_ID
            SEND_PpToSwcSafeFD14Tx_FD14_Segment_2_X1: accessed-variable=PpToSwcSafeFD14Tx.FD14_Segment_2_X1
            SEND_PpToSwcSafeFD14Tx_FD14_Segment_2_X2: accessed-variable=PpToSwcSafeFD14Tx.FD14_Segment_2_X2
            SEND_PpToSwcSafeFD14Tx_FD14_Segment_2_Y1: accessed-variable=PpToSwcSafeFD14Tx.FD14_Segment_2_Y1
            SEND_PpToSwcSafeFD14Tx_FD14_Segment_2_Y2: accessed-variable=PpToSwcSafeFD14Tx.FD14_Segment_2_Y2
            SEND_PpToSwcSafeFD14Tx_FD14_Segment_3_Confidence: accessed-variable=PpToSwcSafeFD14Tx.FD14_Segment_3_Confidence
            SEND_PpToSwcSafeFD14Tx_FD14_Segment_3_ID: accessed-variable=PpToSwcSafeFD14Tx.FD14_Segment_3_ID
            SEND_PpToSwcSafeFD14Tx_FD14_Segment_3_X1: accessed-variable=PpToSwcSafeFD14Tx.FD14_Segment_3_X1
            SEND_PpToSwcSafeFD14Tx_FD14_Segment_3_X2: accessed-variable=PpToSwcSafeFD14Tx.FD14_Segment_3_X2
            SEND_PpToSwcSafeFD14Tx_FD14_Segment_3_Y1: accessed-variable=PpToSwcSafeFD14Tx.FD14_Segment_3_Y1
            SEND_PpToSwcSafeFD14Tx_FD14_Segment_3_Y2: accessed-variable=PpToSwcSafeFD14Tx.FD14_Segment_3_Y2
            SEND_PpToSwcSafeFD14Tx_FD14_Segment_4_Confidence: accessed-variable=PpToSwcSafeFD14Tx.FD14_Segment_4_Confidence
            SEND_PpToSwcSafeFD14Tx_FD14_Segment_4_ID: accessed-variable=PpToSwcSafeFD14Tx.FD14_Segment_4_ID
            SEND_PpToSwcSafeFD14Tx_FD14_Segment_4_X1: accessed-variable=PpToSwcSafeFD14Tx.FD14_Segment_4_X1
            SEND_PpToSwcSafeFD14Tx_FD14_Segment_4_X2: accessed-variable=PpToSwcSafeFD14Tx.FD14_Segment_4_X2
            SEND_PpToSwcSafeFD14Tx_FD14_Segment_4_Y1: accessed-variable=PpToSwcSafeFD14Tx.FD14_Segment_4_Y1
            SEND_PpToSwcSafeFD14Tx_FD14_Segment_4_Y2: accessed-variable=PpToSwcSafeFD14Tx.FD14_Segment_4_Y2
            SEND_PpToSwcSafeFD14Tx_FD14_Segment_5_Confidence: accessed-variable=PpToSwcSafeFD14Tx.FD14_Segment_5_Confidence
            SEND_PpToSwcSafeFD14Tx_FD14_Segment_5_ID: accessed-variable=PpToSwcSafeFD14Tx.FD14_Segment_5_ID
            SEND_PpToSwcSafeFD14Tx_FD14_Segment_5_X1: accessed-variable=PpToSwcSafeFD14Tx.FD14_Segment_5_X1
            SEND_PpToSwcSafeFD14Tx_FD14_Segment_5_X2: accessed-variable=PpToSwcSafeFD14Tx.FD14_Segment_5_X2
            SEND_PpToSwcSafeFD14Tx_FD14_Segment_5_Y1: accessed-variable=PpToSwcSafeFD14Tx.FD14_Segment_5_Y1
            SEND_PpToSwcSafeFD14Tx_FD14_Segment_5_Y2: accessed-variable=PpToSwcSafeFD14Tx.FD14_Segment_5_Y2
            SEND_PpToSwcSafeFD14Tx_FD14_Segment_6_Confidence: accessed-variable=PpToSwcSafeFD14Tx.FD14_Segment_6_Confidence
            SEND_PpToSwcSafeFD14Tx_FD14_Segment_6_ID: accessed-variable=PpToSwcSafeFD14Tx.FD14_Segment_6_ID
            SEND_PpToSwcSafeFD14Tx_FD14_Segment_6_X1: accessed-variable=PpToSwcSafeFD14Tx.FD14_Segment_6_X1
            SEND_PpToSwcSafeFD14Tx_FD14_Segment_6_X2: accessed-variable=PpToSwcSafeFD14Tx.FD14_Segment_6_X2
            SEND_PpToSwcSafeFD14Tx_FD14_Segment_6_Y1: accessed-variable=PpToSwcSafeFD14Tx.FD14_Segment_6_Y1
            SEND_PpToSwcSafeFD14Tx_FD14_Segment_6_Y2: accessed-variable=PpToSwcSafeFD14Tx.FD14_Segment_6_Y2
            SEND_PpToSwcSafeFD14Tx_FD14_Segment_7_Confidence: accessed-variable=PpToSwcSafeFD14Tx.FD14_Segment_7_Confidence
            SEND_PpToSwcSafeFD14Tx_FD14_Segment_7_ID: accessed-variable=PpToSwcSafeFD14Tx.FD14_Segment_7_ID
            SEND_PpToSwcSafeFD14Tx_FD14_Segment_7_X1: accessed-variable=PpToSwcSafeFD14Tx.FD14_Segment_7_X1
            SEND_PpToSwcSafeFD14Tx_FD14_Segment_7_X2: accessed-variable=PpToSwcSafeFD14Tx.FD14_Segment_7_X2
            SEND_PpToSwcSafeFD14Tx_FD14_Segment_7_Y1: accessed-variable=PpToSwcSafeFD14Tx.FD14_Segment_7_Y1
            SEND_PpToSwcSafeFD14Tx_FD14_Segment_7_Y2: accessed-variable=PpToSwcSafeFD14Tx.FD14_Segment_7_Y2
            SEND_PpToSwcSafeFD14Tx_FD14_Segment_8_Confidence: accessed-variable=PpToSwcSafeFD14Tx.FD14_Segment_8_Confidence
            SEND_PpToSwcSafeFD14Tx_FD14_Segment_8_ID: accessed-variable=PpToSwcSafeFD14Tx.FD14_Segment_8_ID
            SEND_PpToSwcSafeFD14Tx_FD14_Segment_8_X1: accessed-variable=PpToSwcSafeFD14Tx.FD14_Segment_8_X1
            SEND_PpToSwcSafeFD14Tx_FD14_Segment_8_X2: accessed-variable=PpToSwcSafeFD14Tx.FD14_Segment_8_X2
            SEND_PpToSwcSafeFD14Tx_FD14_Segment_8_Y1: accessed-variable=PpToSwcSafeFD14Tx.FD14_Segment_8_Y1
            SEND_PpToSwcSafeFD14Tx_FD14_Segment_8_Y2: accessed-variable=PpToSwcSafeFD14Tx.FD14_Segment_8_Y2
            SEND_PpToComSafeFD02Tx_Camera_Status: accessed-variable=PpToComSafeFD02Tx.Camera_Status
            SEND_PpToComSafeFD02Tx_Cntr_ADAS_FD_LANES_1: accessed-variable=PpToComSafeFD02Tx.Cntr_ADAS_FD_LANES_1
            SEND_PpToComSafeFD02Tx_Cntr_ADAS_FD_LANES_2: accessed-variable=PpToComSafeFD02Tx.Cntr_ADAS_FD_LANES_2
            SEND_PpToComSafeFD02Tx_FOD_Confidence: accessed-variable=PpToComSafeFD02Tx.FOD_Confidence
            SEND_PpToComSafeFD02Tx_Frame_Index_Lanes_1: accessed-variable=PpToComSafeFD02Tx.Frame_Index_Lanes_1
            SEND_PpToComSafeFD02Tx_Frame_Index_Lanes_2: accessed-variable=PpToComSafeFD02Tx.Frame_Index_Lanes_2
            SEND_PpToComSafeFD02Tx_Health_Front_Object_Detection: accessed-variable=PpToComSafeFD02Tx.Health_Front_Object_Detection
            SEND_PpToComSafeFD02Tx_Health_Lane_Detection: accessed-variable=PpToComSafeFD02Tx.Health_Lane_Detection
            SEND_PpToComSafeFD02Tx_Line_1_Confidence: accessed-variable=PpToComSafeFD02Tx.Line_1_Confidence
            SEND_PpToComSafeFD02Tx_Line_1_Curvature: accessed-variable=PpToComSafeFD02Tx.Line_1_Curvature
            SEND_PpToComSafeFD02Tx_Line_1_Curvature_Rate: accessed-variable=PpToComSafeFD02Tx.Line_1_Curvature_Rate
            SEND_PpToComSafeFD02Tx_Line_1_End_Range: accessed-variable=PpToComSafeFD02Tx.Line_1_End_Range
            SEND_PpToComSafeFD02Tx_Line_1_Heading: accessed-variable=PpToComSafeFD02Tx.Line_1_Heading
            SEND_PpToComSafeFD02Tx_Line_1_Offset: accessed-variable=PpToComSafeFD02Tx.Line_1_Offset
            SEND_PpToComSafeFD02Tx_Line_1_Start_Range: accessed-variable=PpToComSafeFD02Tx.Line_1_Start_Range
            SEND_PpToComSafeFD02Tx_Line_1_Type: accessed-variable=PpToComSafeFD02Tx.Line_1_Type
            SEND_PpToComSafeFD02Tx_Line_2_Confidence: accessed-variable=PpToComSafeFD02Tx.Line_2_Confidence
            SEND_PpToComSafeFD02Tx_Line_2_Curvature: accessed-variable=PpToComSafeFD02Tx.Line_2_Curvature
            SEND_PpToComSafeFD02Tx_Line_2_Curvature_Rate: accessed-variable=PpToComSafeFD02Tx.Line_2_Curvature_Rate
            SEND_PpToComSafeFD02Tx_Line_2_End_Range: accessed-variable=PpToComSafeFD02Tx.Line_2_End_Range
            SEND_PpToComSafeFD02Tx_Line_2_Heading: accessed-variable=PpToComSafeFD02Tx.Line_2_Heading
            SEND_PpToComSafeFD02Tx_Line_2_Offset: accessed-variable=PpToComSafeFD02Tx.Line_2_Offset
            SEND_PpToComSafeFD02Tx_Line_2_Start_Range: accessed-variable=PpToComSafeFD02Tx.Line_2_Start_Range
            SEND_PpToComSafeFD02Tx_Line_2_Type: accessed-variable=PpToComSafeFD02Tx.Line_2_Type
            SEND_PpToComSafeFD02Tx_Line_3_Confidence: accessed-variable=PpToComSafeFD02Tx.Line_3_Confidence
            SEND_PpToComSafeFD02Tx_Line_3_Curvature: accessed-variable=PpToComSafeFD02Tx.Line_3_Curvature
            SEND_PpToComSafeFD02Tx_Line_3_Curvature_Rate: accessed-variable=PpToComSafeFD02Tx.Line_3_Curvature_Rate
            SEND_PpToComSafeFD02Tx_Line_3_End_Range: accessed-variable=PpToComSafeFD02Tx.Line_3_End_Range
            SEND_PpToComSafeFD02Tx_Line_3_Heading: accessed-variable=PpToComSafeFD02Tx.Line_3_Heading
            SEND_PpToComSafeFD02Tx_Line_3_Offset: accessed-variable=PpToComSafeFD02Tx.Line_3_Offset
            SEND_PpToComSafeFD02Tx_Line_3_Start_Range: accessed-variable=PpToComSafeFD02Tx.Line_3_Start_Range
            SEND_PpToComSafeFD02Tx_Line_3_Type: accessed-variable=PpToComSafeFD02Tx.Line_3_Type
            SEND_PpToComSafeFD02Tx_Line_4_Confidence: accessed-variable=PpToComSafeFD02Tx.Line_4_Confidence
            SEND_PpToComSafeFD02Tx_Line_4_Curvature: accessed-variable=PpToComSafeFD02Tx.Line_4_Curvature
            SEND_PpToComSafeFD02Tx_Line_4_Curvature_Rate: accessed-variable=PpToComSafeFD02Tx.Line_4_Curvature_Rate
            SEND_PpToComSafeFD02Tx_Line_4_End_Range: accessed-variable=PpToComSafeFD02Tx.Line_4_End_Range
            SEND_PpToComSafeFD02Tx_Line_4_Heading: accessed-variable=PpToComSafeFD02Tx.Line_4_Heading
            SEND_PpToComSafeFD02Tx_Line_4_Offset: accessed-variable=PpToComSafeFD02Tx.Line_4_Offset
            SEND_PpToComSafeFD02Tx_Line_4_Start_Range: accessed-variable=PpToComSafeFD02Tx.Line_4_Start_Range
            SEND_PpToComSafeFD02Tx_Line_4_Type: accessed-variable=PpToComSafeFD02Tx.Line_4_Type
            SEND_PpToComSafeFD02Tx_MAC_ADAS_FD_LANES_1: accessed-variable=PpToComSafeFD02Tx.MAC_ADAS_FD_LANES_1
            SEND_PpToComSafeFD02Tx_MAC_ADAS_FD_LANES_2: accessed-variable=PpToComSafeFD02Tx.MAC_ADAS_FD_LANES_2
            SEND_PpToSwcSafeFD02Tx_Camera_Status: accessed-variable=PpToSwcSafeFD02Tx.Camera_Status
            SEND_PpToSwcSafeFD02Tx_Cntr_ADAS_FD_LANES_1: accessed-variable=PpToSwcSafeFD02Tx.Cntr_ADAS_FD_LANES_1
            SEND_PpToSwcSafeFD02Tx_Cntr_ADAS_FD_LANES_2: accessed-variable=PpToSwcSafeFD02Tx.Cntr_ADAS_FD_LANES_2
            SEND_PpToSwcSafeFD02Tx_FOD_Confidence: accessed-variable=PpToSwcSafeFD02Tx.FOD_Confidence
            SEND_PpToSwcSafeFD02Tx_Frame_Index_Lanes_1: accessed-variable=PpToSwcSafeFD02Tx.Frame_Index_Lanes_1
            SEND_PpToSwcSafeFD02Tx_Frame_Index_Lanes_2: accessed-variable=PpToSwcSafeFD02Tx.Frame_Index_Lanes_2
            SEND_PpToSwcSafeFD02Tx_Health_Front_Object_Detection: accessed-variable=PpToSwcSafeFD02Tx.Health_Front_Object_Detection
            SEND_PpToSwcSafeFD02Tx_Health_Lane_Detection: accessed-variable=PpToSwcSafeFD02Tx.Health_Lane_Detection
            SEND_PpToSwcSafeFD02Tx_Line_1_Confidence: accessed-variable=PpToSwcSafeFD02Tx.Line_1_Confidence
            SEND_PpToSwcSafeFD02Tx_Line_1_Curvature: accessed-variable=PpToSwcSafeFD02Tx.Line_1_Curvature
            SEND_PpToSwcSafeFD02Tx_Line_1_Curvature_Rate: accessed-variable=PpToSwcSafeFD02Tx.Line_1_Curvature_Rate
            SEND_PpToSwcSafeFD02Tx_Line_1_End_Range: accessed-variable=PpToSwcSafeFD02Tx.Line_1_End_Range
            SEND_PpToSwcSafeFD02Tx_Line_1_Heading: accessed-variable=PpToSwcSafeFD02Tx.Line_1_Heading
            SEND_PpToSwcSafeFD02Tx_Line_1_Offset: accessed-variable=PpToSwcSafeFD02Tx.Line_1_Offset
            SEND_PpToSwcSafeFD02Tx_Line_1_Start_Range: accessed-variable=PpToSwcSafeFD02Tx.Line_1_Start_Range
            SEND_PpToSwcSafeFD02Tx_Line_1_Type: accessed-variable=PpToSwcSafeFD02Tx.Line_1_Type
            SEND_PpToSwcSafeFD02Tx_Line_2_Confidence: accessed-variable=PpToSwcSafeFD02Tx.Line_2_Confidence
            SEND_PpToSwcSafeFD02Tx_Line_2_Curvature: accessed-variable=PpToSwcSafeFD02Tx.Line_2_Curvature
            SEND_PpToSwcSafeFD02Tx_Line_2_Curvature_Rate: accessed-variable=PpToSwcSafeFD02Tx.Line_2_Curvature_Rate
            SEND_PpToSwcSafeFD02Tx_Line_2_End_Range: accessed-variable=PpToSwcSafeFD02Tx.Line_2_End_Range
            SEND_PpToSwcSafeFD02Tx_Line_2_Heading: accessed-variable=PpToSwcSafeFD02Tx.Line_2_Heading
            SEND_PpToSwcSafeFD02Tx_Line_2_Offset: accessed-variable=PpToSwcSafeFD02Tx.Line_2_Offset
            SEND_PpToSwcSafeFD02Tx_Line_2_Start_Range: accessed-variable=PpToSwcSafeFD02Tx.Line_2_Start_Range
            SEND_PpToSwcSafeFD02Tx_Line_2_Type: accessed-variable=PpToSwcSafeFD02Tx.Line_2_Type
            SEND_PpToSwcSafeFD02Tx_Line_3_Confidence: accessed-variable=PpToSwcSafeFD02Tx.Line_3_Confidence
            SEND_PpToSwcSafeFD02Tx_Line_3_Curvature: accessed-variable=PpToSwcSafeFD02Tx.Line_3_Curvature
            SEND_PpToSwcSafeFD02Tx_Line_3_Curvature_Rate: accessed-variable=PpToSwcSafeFD02Tx.Line_3_Curvature_Rate
            SEND_PpToSwcSafeFD02Tx_Line_3_End_Range: accessed-variable=PpToSwcSafeFD02Tx.Line_3_End_Range
            SEND_PpToSwcSafeFD02Tx_Line_3_Heading: accessed-variable=PpToSwcSafeFD02Tx.Line_3_Heading
            SEND_PpToSwcSafeFD02Tx_Line_3_Offset: accessed-variable=PpToSwcSafeFD02Tx.Line_3_Offset
            SEND_PpToSwcSafeFD02Tx_Line_3_Start_Range: accessed-variable=PpToSwcSafeFD02Tx.Line_3_Start_Range
            SEND_PpToSwcSafeFD02Tx_Line_3_Type: accessed-variable=PpToSwcSafeFD02Tx.Line_3_Type
            SEND_PpToSwcSafeFD02Tx_Line_4_Confidence: accessed-variable=PpToSwcSafeFD02Tx.Line_4_Confidence
            SEND_PpToSwcSafeFD02Tx_Line_4_Curvature: accessed-variable=PpToSwcSafeFD02Tx.Line_4_Curvature
            SEND_PpToSwcSafeFD02Tx_Line_4_Curvature_Rate: accessed-variable=PpToSwcSafeFD02Tx.Line_4_Curvature_Rate
            SEND_PpToSwcSafeFD02Tx_Line_4_End_Range: accessed-variable=PpToSwcSafeFD02Tx.Line_4_End_Range
            SEND_PpToSwcSafeFD02Tx_Line_4_Heading: accessed-variable=PpToSwcSafeFD02Tx.Line_4_Heading
            SEND_PpToSwcSafeFD02Tx_Line_4_Offset: accessed-variable=PpToSwcSafeFD02Tx.Line_4_Offset
            SEND_PpToSwcSafeFD02Tx_Line_4_Start_Range: accessed-variable=PpToSwcSafeFD02Tx.Line_4_Start_Range
            SEND_PpToSwcSafeFD02Tx_Line_4_Type: accessed-variable=PpToSwcSafeFD02Tx.Line_4_Type
            SEND_PpToSwcSafeFD02Tx_MAC_ADAS_FD_LANES_1: accessed-variable=PpToSwcSafeFD02Tx.MAC_ADAS_FD_LANES_1
            SEND_PpToSwcSafeFD02Tx_MAC_ADAS_FD_LANES_2: accessed-variable=PpToSwcSafeFD02Tx.MAC_ADAS_FD_LANES_2
            SEND_PpToComSafeFD02Tx_Reserved_for_functional_safety: accessed-variable=PpToComSafeFD02Tx.Reserved_for_functional_safety
            SEND_PpToComSafeFD02Tx_Segment_1_Confidence: accessed-variable=PpToComSafeFD02Tx.Segment_1_Confidence
            SEND_PpToComSafeFD02Tx_Segment_1_ID: accessed-variable=PpToComSafeFD02Tx.Segment_1_ID
            SEND_PpToComSafeFD02Tx_Segment_1_X1: accessed-variable=PpToComSafeFD02Tx.Segment_1_X1
            SEND_PpToComSafeFD02Tx_Segment_1_X2: accessed-variable=PpToComSafeFD02Tx.Segment_1_X2
            SEND_PpToComSafeFD02Tx_Segment_1_Y1: accessed-variable=PpToComSafeFD02Tx.Segment_1_Y1
            SEND_PpToComSafeFD02Tx_Segment_1_Y2: accessed-variable=PpToComSafeFD02Tx.Segment_1_Y2
            SEND_PpToComSafeFD02Tx_Segment_2_Confidence: accessed-variable=PpToComSafeFD02Tx.Segment_2_Confidence
            SEND_PpToComSafeFD02Tx_Segment_2_ID: accessed-variable=PpToComSafeFD02Tx.Segment_2_ID
            SEND_PpToComSafeFD02Tx_Segment_2_X1: accessed-variable=PpToComSafeFD02Tx.Segment_2_X1
            SEND_PpToComSafeFD02Tx_Segment_2_X2: accessed-variable=PpToComSafeFD02Tx.Segment_2_X2
            SEND_PpToComSafeFD02Tx_Segment_2_Y1: accessed-variable=PpToComSafeFD02Tx.Segment_2_Y1
            SEND_PpToComSafeFD02Tx_Segment_2_Y2: accessed-variable=PpToComSafeFD02Tx.Segment_2_Y2
            SEND_PpToComSafeFD02Tx_Segment_3_Confidence: accessed-variable=PpToComSafeFD02Tx.Segment_3_Confidence
            SEND_PpToComSafeFD02Tx_Segment_3_ID: accessed-variable=PpToComSafeFD02Tx.Segment_3_ID
            SEND_PpToComSafeFD02Tx_Segment_3_X1: accessed-variable=PpToComSafeFD02Tx.Segment_3_X1
            SEND_PpToComSafeFD02Tx_Segment_3_X2: accessed-variable=PpToComSafeFD02Tx.Segment_3_X2
            SEND_PpToComSafeFD02Tx_Segment_3_Y1: accessed-variable=PpToComSafeFD02Tx.Segment_3_Y1
            SEND_PpToComSafeFD02Tx_Segment_3_Y2: accessed-variable=PpToComSafeFD02Tx.Segment_3_Y2
            SEND_PpToComSafeFD02Tx_Segment_4_Confidence: accessed-variable=PpToComSafeFD02Tx.Segment_4_Confidence
            SEND_PpToComSafeFD02Tx_Segment_4_ID: accessed-variable=PpToComSafeFD02Tx.Segment_4_ID
            SEND_PpToComSafeFD02Tx_Segment_4_X1: accessed-variable=PpToComSafeFD02Tx.Segment_4_X1
            SEND_PpToComSafeFD02Tx_Segment_4_X2: accessed-variable=PpToComSafeFD02Tx.Segment_4_X2
            SEND_PpToComSafeFD02Tx_Segment_4_Y1: accessed-variable=PpToComSafeFD02Tx.Segment_4_Y1
            SEND_PpToComSafeFD02Tx_Segment_4_Y2: accessed-variable=PpToComSafeFD02Tx.Segment_4_Y2
            SEND_PpToComSafeFD02Tx_Segment_5_Confidence: accessed-variable=PpToComSafeFD02Tx.Segment_5_Confidence
            SEND_PpToComSafeFD02Tx_Segment_5_ID: accessed-variable=PpToComSafeFD02Tx.Segment_5_ID
            SEND_PpToComSafeFD02Tx_Segment_5_X1: accessed-variable=PpToComSafeFD02Tx.Segment_5_X1
            SEND_PpToComSafeFD02Tx_Segment_5_X2: accessed-variable=PpToComSafeFD02Tx.Segment_5_X2
            SEND_PpToComSafeFD02Tx_Segment_5_Y1: accessed-variable=PpToComSafeFD02Tx.Segment_5_Y1
            SEND_PpToComSafeFD02Tx_Segment_5_Y2: accessed-variable=PpToComSafeFD02Tx.Segment_5_Y2
            SEND_PpToComSafeFD02Tx_Segment_6_Confidence: accessed-variable=PpToComSafeFD02Tx.Segment_6_Confidence
            SEND_PpToComSafeFD02Tx_Segment_6_ID: accessed-variable=PpToComSafeFD02Tx.Segment_6_ID
            SEND_PpToComSafeFD02Tx_Segment_6_X1: accessed-variable=PpToComSafeFD02Tx.Segment_6_X1
            SEND_PpToComSafeFD02Tx_Segment_6_X2: accessed-variable=PpToComSafeFD02Tx.Segment_6_X2
            SEND_PpToComSafeFD02Tx_Segment_6_Y1: accessed-variable=PpToComSafeFD02Tx.Segment_6_Y1
            SEND_PpToComSafeFD02Tx_Segment_6_Y2: accessed-variable=PpToComSafeFD02Tx.Segment_6_Y2
            SEND_PpToComSafeFD02Tx_Segment_7_Confidence: accessed-variable=PpToComSafeFD02Tx.Segment_7_Confidence
            SEND_PpToComSafeFD02Tx_Segment_7_ID: accessed-variable=PpToComSafeFD02Tx.Segment_7_ID
            SEND_PpToComSafeFD02Tx_Segment_7_X1: accessed-variable=PpToComSafeFD02Tx.Segment_7_X1
            SEND_PpToComSafeFD02Tx_Segment_7_X2: accessed-variable=PpToComSafeFD02Tx.Segment_7_X2
            SEND_PpToComSafeFD02Tx_Segment_7_Y1: accessed-variable=PpToComSafeFD02Tx.Segment_7_Y1
            SEND_PpToComSafeFD02Tx_Segment_7_Y2: accessed-variable=PpToComSafeFD02Tx.Segment_7_Y2
            SEND_PpToComSafeFD02Tx_Segment_8_Confidence: accessed-variable=PpToComSafeFD02Tx.Segment_8_Confidence
            SEND_PpToComSafeFD02Tx_Segment_8_ID: accessed-variable=PpToComSafeFD02Tx.Segment_8_ID
            SEND_PpToComSafeFD02Tx_Segment_8_X1: accessed-variable=PpToComSafeFD02Tx.Segment_8_X1
            SEND_PpToComSafeFD02Tx_Segment_8_X2: accessed-variable=PpToComSafeFD02Tx.Segment_8_X2
            SEND_PpToComSafeFD02Tx_Segment_8_Y1: accessed-variable=PpToComSafeFD02Tx.Segment_8_Y1
            SEND_PpToComSafeFD02Tx_Segment_8_Y2: accessed-variable=PpToComSafeFD02Tx.Segment_8_Y2
            SEND_PpToSwcSafeFD02Tx_Reserved_for_functional_safety: accessed-variable=PpToSwcSafeFD02Tx.Reserved_for_functional_safety
            SEND_PpToSwcSafeFD02Tx_Segment_1_Confidence: accessed-variable=PpToSwcSafeFD02Tx.Segment_1_Confidence
            SEND_PpToSwcSafeFD02Tx_Segment_1_ID: accessed-variable=PpToSwcSafeFD02Tx.Segment_1_ID
            SEND_PpToSwcSafeFD02Tx_Segment_1_X1: accessed-variable=PpToSwcSafeFD02Tx.Segment_1_X1
            SEND_PpToSwcSafeFD02Tx_Segment_1_X2: accessed-variable=PpToSwcSafeFD02Tx.Segment_1_X2
            SEND_PpToSwcSafeFD02Tx_Segment_1_Y1: accessed-variable=PpToSwcSafeFD02Tx.Segment_1_Y1
            SEND_PpToSwcSafeFD02Tx_Segment_1_Y2: accessed-variable=PpToSwcSafeFD02Tx.Segment_1_Y2
            SEND_PpToSwcSafeFD02Tx_Segment_2_Confidence: accessed-variable=PpToSwcSafeFD02Tx.Segment_2_Confidence
            SEND_PpToSwcSafeFD02Tx_Segment_2_ID: accessed-variable=PpToSwcSafeFD02Tx.Segment_2_ID
            SEND_PpToSwcSafeFD02Tx_Segment_2_X1: accessed-variable=PpToSwcSafeFD02Tx.Segment_2_X1
            SEND_PpToSwcSafeFD02Tx_Segment_2_X2: accessed-variable=PpToSwcSafeFD02Tx.Segment_2_X2
            SEND_PpToSwcSafeFD02Tx_Segment_2_Y1: accessed-variable=PpToSwcSafeFD02Tx.Segment_2_Y1
            SEND_PpToSwcSafeFD02Tx_Segment_2_Y2: accessed-variable=PpToSwcSafeFD02Tx.Segment_2_Y2
            SEND_PpToSwcSafeFD02Tx_Segment_3_Confidence: accessed-variable=PpToSwcSafeFD02Tx.Segment_3_Confidence
            SEND_PpToSwcSafeFD02Tx_Segment_3_ID: accessed-variable=PpToSwcSafeFD02Tx.Segment_3_ID
            SEND_PpToSwcSafeFD02Tx_Segment_3_X1: accessed-variable=PpToSwcSafeFD02Tx.Segment_3_X1
            SEND_PpToSwcSafeFD02Tx_Segment_3_X2: accessed-variable=PpToSwcSafeFD02Tx.Segment_3_X2
            SEND_PpToSwcSafeFD02Tx_Segment_3_Y1: accessed-variable=PpToSwcSafeFD02Tx.Segment_3_Y1
            SEND_PpToSwcSafeFD02Tx_Segment_3_Y2: accessed-variable=PpToSwcSafeFD02Tx.Segment_3_Y2
            SEND_PpToSwcSafeFD02Tx_Segment_4_Confidence: accessed-variable=PpToSwcSafeFD02Tx.Segment_4_Confidence
            SEND_PpToSwcSafeFD02Tx_Segment_4_ID: accessed-variable=PpToSwcSafeFD02Tx.Segment_4_ID
            SEND_PpToSwcSafeFD02Tx_Segment_4_X1: accessed-variable=PpToSwcSafeFD02Tx.Segment_4_X1
            SEND_PpToSwcSafeFD02Tx_Segment_4_X2: accessed-variable=PpToSwcSafeFD02Tx.Segment_4_X2
            SEND_PpToSwcSafeFD02Tx_Segment_4_Y1: accessed-variable=PpToSwcSafeFD02Tx.Segment_4_Y1
            SEND_PpToSwcSafeFD02Tx_Segment_4_Y2: accessed-variable=PpToSwcSafeFD02Tx.Segment_4_Y2
            SEND_PpToSwcSafeFD02Tx_Segment_5_Confidence: accessed-variable=PpToSwcSafeFD02Tx.Segment_5_Confidence
            SEND_PpToSwcSafeFD02Tx_Segment_5_ID: accessed-variable=PpToSwcSafeFD02Tx.Segment_5_ID
            SEND_PpToSwcSafeFD02Tx_Segment_5_X1: accessed-variable=PpToSwcSafeFD02Tx.Segment_5_X1
            SEND_PpToSwcSafeFD02Tx_Segment_5_X2: accessed-variable=PpToSwcSafeFD02Tx.Segment_5_X2
            SEND_PpToSwcSafeFD02Tx_Segment_5_Y1: accessed-variable=PpToSwcSafeFD02Tx.Segment_5_Y1
            SEND_PpToSwcSafeFD02Tx_Segment_5_Y2: accessed-variable=PpToSwcSafeFD02Tx.Segment_5_Y2
            SEND_PpToSwcSafeFD02Tx_Segment_6_Confidence: accessed-variable=PpToSwcSafeFD02Tx.Segment_6_Confidence
            SEND_PpToSwcSafeFD02Tx_Segment_6_ID: accessed-variable=PpToSwcSafeFD02Tx.Segment_6_ID
            SEND_PpToSwcSafeFD02Tx_Segment_6_X1: accessed-variable=PpToSwcSafeFD02Tx.Segment_6_X1
            SEND_PpToSwcSafeFD02Tx_Segment_6_X2: accessed-variable=PpToSwcSafeFD02Tx.Segment_6_X2
            SEND_PpToSwcSafeFD02Tx_Segment_6_Y1: accessed-variable=PpToSwcSafeFD02Tx.Segment_6_Y1
            SEND_PpToSwcSafeFD02Tx_Segment_6_Y2: accessed-variable=PpToSwcSafeFD02Tx.Segment_6_Y2
            SEND_PpToSwcSafeFD02Tx_Segment_7_Confidence: accessed-variable=PpToSwcSafeFD02Tx.Segment_7_Confidence
            SEND_PpToSwcSafeFD02Tx_Segment_7_ID: accessed-variable=PpToSwcSafeFD02Tx.Segment_7_ID
            SEND_PpToSwcSafeFD02Tx_Segment_7_X1: accessed-variable=PpToSwcSafeFD02Tx.Segment_7_X1
            SEND_PpToSwcSafeFD02Tx_Segment_7_X2: accessed-variable=PpToSwcSafeFD02Tx.Segment_7_X2
            SEND_PpToSwcSafeFD02Tx_Segment_7_Y1: accessed-variable=PpToSwcSafeFD02Tx.Segment_7_Y1
            SEND_PpToSwcSafeFD02Tx_Segment_7_Y2: accessed-variable=PpToSwcSafeFD02Tx.Segment_7_Y2
            SEND_PpToSwcSafeFD02Tx_Segment_8_Confidence: accessed-variable=PpToSwcSafeFD02Tx.Segment_8_Confidence
            SEND_PpToSwcSafeFD02Tx_Segment_8_ID: accessed-variable=PpToSwcSafeFD02Tx.Segment_8_ID
            SEND_PpToSwcSafeFD02Tx_Segment_8_X1: accessed-variable=PpToSwcSafeFD02Tx.Segment_8_X1
            SEND_PpToSwcSafeFD02Tx_Segment_8_X2: accessed-variable=PpToSwcSafeFD02Tx.Segment_8_X2
            SEND_PpToSwcSafeFD02Tx_Segment_8_Y1: accessed-variable=PpToSwcSafeFD02Tx.Segment_8_Y1
            SEND_PpToSwcSafeFD02Tx_Segment_8_Y2: accessed-variable=PpToSwcSafeFD02Tx.Segment_8_Y2
            SEND_PpToComDbgSafeFD14Tx_FD14_1_ErrFaultInfo_MCU2_0: accessed-variable=PpToComDbgSafeFD14Tx.FD14_1_ErrFaultInfo_MCU2_0
            SEND_PpToComDbgSafeFD14Tx_FD14_1_Err_FaultInfo_MCU1_0: accessed-variable=PpToComDbgSafeFD14Tx.FD14_1_Err_FaultInfo_MCU1_0
            SEND_PpToComDbgSafeFD14Tx_FD14_1_Err_FaultInfo_MCU2_1: accessed-variable=PpToComDbgSafeFD14Tx.FD14_1_Err_FaultInfo_MCU2_1
            SEND_PpToComDbgSafeFD14Tx_FD14_1_Err_FaultInfo_MPU1_0: accessed-variable=PpToComDbgSafeFD14Tx.FD14_1_Err_FaultInfo_MPU1_0
            SEND_PpToComDbgSafeFD14Tx_FD14_1_Err_FaultNum_MCU1_0: accessed-variable=PpToComDbgSafeFD14Tx.FD14_1_Err_FaultNum_MCU1_0
            SEND_PpToComDbgSafeFD14Tx_FD14_1_Err_FaultNum_MCU2_0: accessed-variable=PpToComDbgSafeFD14Tx.FD14_1_Err_FaultNum_MCU2_0
            SEND_PpToComDbgSafeFD14Tx_FD14_1_Err_FaultNum_MCU2_1: accessed-variable=PpToComDbgSafeFD14Tx.FD14_1_Err_FaultNum_MCU2_1
            SEND_PpToComDbgSafeFD14Tx_FD14_1_Err_FaultNum_MPU1_0: accessed-variable=PpToComDbgSafeFD14Tx.FD14_1_Err_FaultNum_MPU1_0
            SEND_PpToComDbgSafeFD14Tx_FD14_1_Reserved_MCU1_0: accessed-variable=PpToComDbgSafeFD14Tx.FD14_1_Reserved_MCU1_0
            SEND_PpToComDbgSafeFD14Tx_FD14_1_Reserved_MCU2_0: accessed-variable=PpToComDbgSafeFD14Tx.FD14_1_Reserved_MCU2_0
            SEND_PpToComDbgSafeFD14Tx_FD14_1_Reserved_MCU2_1: accessed-variable=PpToComDbgSafeFD14Tx.FD14_1_Reserved_MCU2_1
            SEND_PpToComDbgSafeFD14Tx_FD14_1_Reserved_MPU1_0: accessed-variable=PpToComDbgSafeFD14Tx.FD14_1_Reserved_MPU1_0
            SEND_PpToComDbgSafeFD14Tx_FD14_1_SDL_Fault_MCU1_0: accessed-variable=PpToComDbgSafeFD14Tx.FD14_1_SDL_Fault_MCU1_0
            SEND_PpToComDbgSafeFD14Tx_FD14_1_SSM_FltData{10..18}_MCU1_0: accessed-variable=PpToComDbgSafeFD14Tx.FD14_1_SSM_FltData{10..18}_MCU1_0
            SEND_PpToComDbgSafeFD14Tx_FD14_1_SSM_FltData{1..9}_MCU1_0: accessed-variable=PpToComDbgSafeFD14Tx.FD14_1_SSM_FltData{1..9}_MCU1_0
            SEND_PpToComDbgSafeFD14Tx_FD14_1_WDG_Error_ID_MCU1_0: accessed-variable=PpToComDbgSafeFD14Tx.FD14_1_WDG_Error_ID_MCU1_0
            SEND_PpToComDbgSafeFD14Tx_FD14_1_Hook_DtErr_MCU1_0: accessed-variable=PpToComDbgSafeFD14Tx.FD14_1_Hook_DtErr_MCU1_0
            SEND_PpToComDbgSafeFD14Tx_FD14_1_Hook_Error_MCU1_0: accessed-variable=PpToComDbgSafeFD14Tx.FD14_1_Hook_Error_MCU1_0
            SEND_PpToComDbgSafeFD14Tx_FD14_1_Hook_PresentPtr_MCU1_0: accessed-variable=PpToComDbgSafeFD14Tx.FD14_1_Hook_PresentPtr_MCU1_0
            SEND_PpToComDbgSafeFD14Tx_FD14_1_Hook_Reserved_MCU1_0: accessed-variable=PpToComDbgSafeFD14Tx.FD14_1_Hook_Reserved_MCU1_0
            SEND_PpToComDbgSafeFD14Tx_FD14_1_Hook_Service_MCU1_0: accessed-variable=PpToComDbgSafeFD14Tx.FD14_1_Hook_Service_MCU1_0
            SEND_PpToComDbgSafeFD14Tx_FD14_1_Hook_Type_MCU1_0: accessed-variable=PpToComDbgSafeFD14Tx.FD14_1_Hook_Type_MCU1_0
            SEND_PpToComDbgSafeFD14Tx_FD14_1_Hook_actTsk_MCU1_0: accessed-variable=PpToComDbgSafeFD14Tx.FD14_1_Hook_actTsk_MCU1_0
            SEND_PpToComDbgSafeFD14Tx_FD14_1_Hook_fatalErr_MCU1_0: accessed-variable=PpToComDbgSafeFD14Tx.FD14_1_Hook_fatalErr_MCU1_0
            SEND_PpToComDbgSafeFD14Tx_FD14_1_AliveCntr_MCU2_0: accessed-variable=PpToComDbgSafeFD14Tx.FD14_1_AliveCntr_MCU2_0
            SEND_PpToComDbgSafeFD14Tx_FD14_1_AliveCntr_MCU2_1: accessed-variable=PpToComDbgSafeFD14Tx.FD14_1_AliveCntr_MCU2_1
            SEND_PpToComDbgSafeFD14Tx_FD14_1_AliveCntr_MPU1_0: accessed-variable=PpToComDbgSafeFD14Tx.FD14_1_AliveCntr_MPU1_0
            SEND_PpToComDbgSafeFD14Tx_FD14_1_OsRegMCU_ADFSR: accessed-variable=PpToComDbgSafeFD14Tx.FD14_1_OsRegMCU_ADFSR
            SEND_PpToComDbgSafeFD14Tx_FD14_1_OsRegMCU_AIFSR: accessed-variable=PpToComDbgSafeFD14Tx.FD14_1_OsRegMCU_AIFSR
            SEND_PpToComDbgSafeFD14Tx_FD14_1_OsRegMCU_DFAR: accessed-variable=PpToComDbgSafeFD14Tx.FD14_1_OsRegMCU_DFAR
            SEND_PpToComDbgSafeFD14Tx_FD14_1_OsRegMCU_DFSR: accessed-variable=PpToComDbgSafeFD14Tx.FD14_1_OsRegMCU_DFSR
            SEND_PpToComDbgSafeFD14Tx_FD14_1_OsRegMCU_IFAR: accessed-variable=PpToComDbgSafeFD14Tx.FD14_1_OsRegMCU_IFAR
            SEND_PpToComDbgSafeFD14Tx_FD14_1_OsRegMCU_IFSR: accessed-variable=PpToComDbgSafeFD14Tx.FD14_1_OsRegMCU_IFSR
            SEND_PpToComDbgSafeFD14Tx_FD14_1_OsRegMCU_Link: accessed-variable=PpToComDbgSafeFD14Tx.FD14_1_OsRegMCU_Link
            SEND_PpToComDbgSafeFD14Tx_FD14_1_OsRegMCU_SPSR: accessed-variable=PpToComDbgSafeFD14Tx.FD14_1_OsRegMCU_SPSR
            SEND_PpToComDbgSafeFD14Tx_FD14_1_OsRegMCU_Stack{0..9}: accessed-variable=PpToComDbgSafeFD14Tx.FD14_1_OsRegMCU_Stack{0..9}
            SEND_PpToComDbgSafeFD14Tx_FD14_1_SSM_SystemStateReq: accessed-variable=PpToComDbgSafeFD14Tx.FD14_1_SSM_SystemStateReq
            SEND_PpToComDbgSafeFD14Tx_FD14_1_TimeSincePowerON: accessed-variable=PpToComDbgSafeFD14Tx.FD14_1_TimeSincePowerON
        sync call SC_RpE2EServices_ME_E2E_Protect: operation=RpE2EServices.ME_E2E_Protect
  swc implementation SWC_SafeVCANTx_Implementation: behavior=SWC_SafeVCANTx_InternalBehavior
